AUTOSAR XML (schema 00048)
package /ComponentTypes
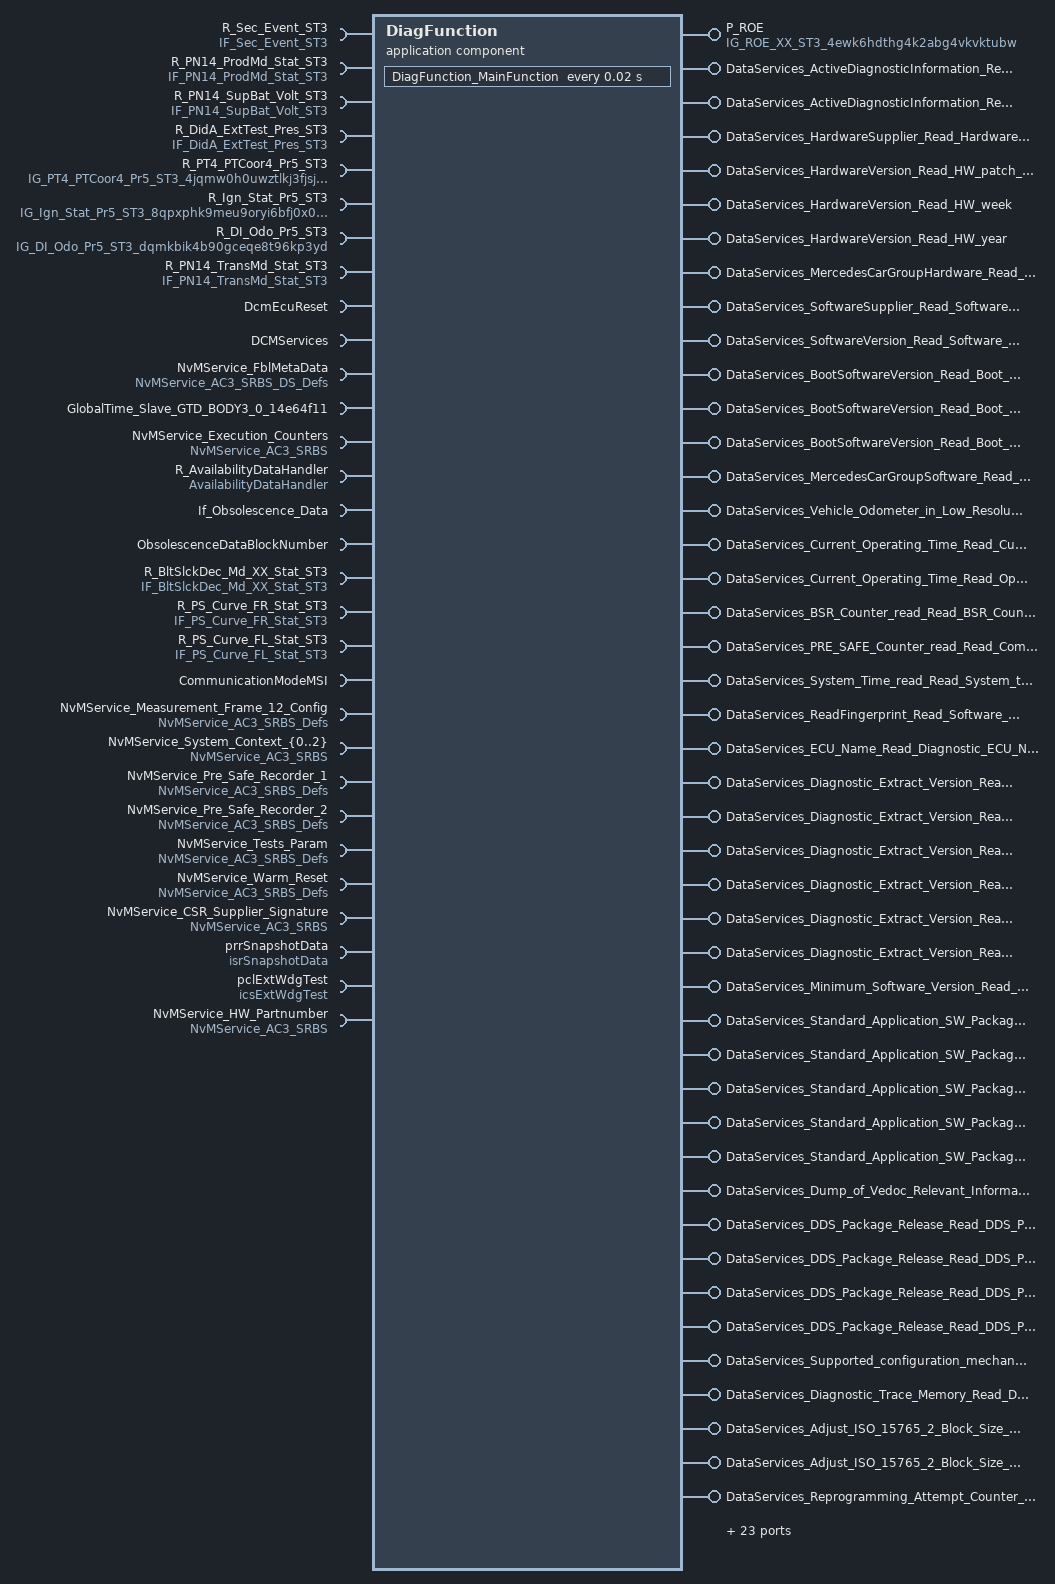
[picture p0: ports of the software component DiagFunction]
  application sw component type DiagFunction
    provide port P_ROE: nonqueued-sender-com-spec{data-element=ROE_XX_ST3, init-value=constant-reference=XDIS_epntk9hnintc34egvtksqi4oo}, provided-interface=IG_ROE_XX_ST3_4ewk6hdthg4k2abg4vkvktubw  # Response on Event (degraded)
    9 x require port:
      R_Sec_Event_ST3: nonqueued-receiver-com-spec{data-element=Data, init-value=constant-reference=XDIS_6146w3b2vgdunnu49c413rpbf}, required-interface=IF_Sec_Event_ST3  # Security event
      R_PN14_ProdMd_Stat_ST3: nonqueued-receiver-com-spec{data-element=PN14_ProdMd_Stat_ST3, init-value=constant-reference=XDIS_1sbl03n5g1wzhawz3y1aoi9p4}, required-interface=IF_PN14_ProdMd_Stat_ST3  # Powernet production mode state
      R_PN14_SupBat_Volt_ST3: nonqueued-receiver-com-spec{data-element=PN14_SupBat_Volt_ST3, init-value=constant-reference=XDIS_1d3ai2d8h1n3nb7ayhambew4d}, required-interface=IF_PN14_SupBat_Volt_ST3  # Supply battery voltage
      R_DidA_ExtTest_Pres_ST3: nonqueued-receiver-com-spec{data-element=DidA_ExtTest_Pres_ST3, init-value=constant-reference=XDIS_ays1a6ktv25pr5ggjl5ntdf5h}, required-interface=IF_DidA_ExtTest_Pres_ST3  # DidA external tester present
      R_PT4_PTCoor4_Pr5_ST3: nonqueued-receiver-com-spec{data-element=PT4_PTCoor4_Pr5_ST3, end-to-end-transformation-com-spec-props=disable-end-to-end-check=true, init-value=constant-reference=XDIS_9yh6bo4rxot1fkk0920219751}, required-interface=IG_PT4_PTCoor4_Pr5_ST3_4jqmw0h0uwztlkj3fjsj9fpfe  # PT4_PTCoor4_Pr5_ST3 (degraded)
      R_Ign_Stat_Pr5_ST3: nonqueued-receiver-com-spec{data-element=Ign_Stat_Pr5_ST3, end-to-end-transformation-com-spec-props=disable-end-to-end-check=false, enable-update=true, filter=data-filter-type=ALWAYS, init-value=constant-reference=XDIS_cfagkw6zyn9r952v5onwpwdur}, required-interface=IG_Ign_Stat_Pr5_ST3_8qpxphk9meu9oryi6bfj0x04b  # Ignition state (degraded)
      R_DI_Odo_Pr5_ST3: nonqueued-receiver-com-spec{data-element=DI_Odo_Pr5_ST3, end-to-end-transformation-com-spec-props=disable-end-to-end-check=true, init-value=constant-reference=XDIS_6b75pabydagdo3iwsn1mn0uh1}, required-interface=IG_DI_Odo_Pr5_ST3_dqmkbik4b90gceqe8t96kp3yd  # DriverInformation Odometer (degraded)
      R_PN14_TransMd_Stat_ST3: nonqueued-receiver-com-spec{data-element=PN14_TransMd_Stat_ST3, filter=data-filter-type=ALWAYS, init-value=constant-reference=XDIS_csegq0grcmpyfro5u6kyzxmql}, required-interface=IF_PN14_TransMd_Stat_ST3  # Powernet transport mode status
      DcmEcuReset: mode-switch-receiver-com-spec=DcmEcuReset, required-interface=DcmEcuReset
    43 x provide port:
      DataServices_ActiveDiagnosticInformation_Read_Identification: provided-com-specs=[{operation=ConditionCheckRead, queue-length=1}, {operation=ReadData, queue-length=1}], provided-interface=DataServices_ActiveDiagnosticInformation_Read_Identification
      DataServices_ActiveDiagnosticInformation_Read_Session: provided-com-specs=[{operation=ConditionCheckRead, queue-length=1}, {operation=ReadData, queue-length=1}], provided-interface=DataServices_ActiveDiagnosticInformation_Read_Session
      DataServices_HardwareSupplier_Read_Hardware_Supplier_Identification: provided-com-specs=[{operation=ConditionCheckRead, queue-length=1}, {operation=ReadData, queue-length=1}], provided-interface=DataServices_HardwareSupplier_Read_Hardware_Supplier_Identification
      DataServices_HardwareVersion_Read_HW_patch_level: provided-com-specs=[{operation=ConditionCheckRead, queue-length=1}, {operation=ReadData, queue-length=1}], provided-interface=DataServices_HardwareVersion_Read_HW_patch_level
      DataServices_HardwareVersion_Read_HW_week: provided-com-specs=[{operation=ConditionCheckRead, queue-length=1}, {operation=ReadData, queue-length=1}], provided-interface=DataServices_HardwareVersion_Read_HW_week
      DataServices_HardwareVersion_Read_HW_year: provided-com-specs=[{operation=ConditionCheckRead, queue-length=1}, {operation=ReadData, queue-length=1}], provided-interface=DataServices_HardwareVersion_Read_HW_year
      DataServices_MercedesCarGroupHardware_Read_Hardware_Part_Number: provided-com-specs=[{operation=ConditionCheckRead, queue-length=1}, {operation=ReadData, queue-length=1}], provided-interface=DataServices_MercedesCarGroupHardware_Read_Hardware_Part_Number
      DataServices_SoftwareSupplier_Read_Software_Logical_Block_Supplier_Identification: provided-interface=DataServices_SoftwareSupplier_Read_Software_Logical_Block_Supplier_Identification
        provided-com-specs:
          operation=ConditionCheckRead, queue-length=1
          operation=ReadDataLength, queue-length=1
          operation=ReadData, queue-length=1
      DataServices_SoftwareVersion_Read_Software_Logical_Block_Version_Information: provided-interface=DataServices_SoftwareVersion_Read_Software_Logical_Block_Version_Information
        provided-com-specs:
          operation=ConditionCheckRead, queue-length=1
          operation=ReadDataLength, queue-length=1
          operation=ReadData, queue-length=1
      DataServices_BootSoftwareVersion_Read_Boot_SW_year: provided-com-specs=[{operation=ConditionCheckRead, queue-length=1}, {operation=ReadData, queue-length=1}], provided-interface=DataServices_BootSoftwareVersion_Read_Boot_SW_year
      DataServices_BootSoftwareVersion_Read_Boot_SW_week: provided-com-specs=[{operation=ConditionCheckRead, queue-length=1}, {operation=ReadData, queue-length=1}], provided-interface=DataServices_BootSoftwareVersion_Read_Boot_SW_week
      DataServices_BootSoftwareVersion_Read_Boot_SW_patch_level: provided-com-specs=[{operation=ConditionCheckRead, queue-length=1}, {operation=ReadData, queue-length=1}], provided-interface=DataServices_BootSoftwareVersion_Read_Boot_SW_patch_level
      DataServices_MercedesCarGroupSoftware_Read_Software_Logical_Block_Numbers: provided-interface=DataServices_MercedesCarGroupSoftware_Read_Software_Logical_Block_Numbers
        provided-com-specs:
          operation=ConditionCheckRead, queue-length=1
          operation=ReadDataLength, queue-length=1
          operation=ReadData, queue-length=1
      DataServices_Vehicle_Odometer_in_Low_Resolution_Read_Vehicle_Odometer_in_Low_Resolution: provided-com-specs=[{operation=ConditionCheckRead, queue-length=1}, {operation=ReadData, queue-length=1}], provided-interface=DataServices_Vehicle_Odometer_in_Low_Resolution_Read_Vehicle_Odometer_in_Low_Resolution
      DataServices_Current_Operating_Time_Read_Current_Operating_Time: provided-com-specs=[{operation=ConditionCheckRead, queue-length=1}, {operation=ReadData, queue-length=1}], provided-interface=DataServices_Current_Operating_Time_Read_Current_Operating_Time
      DataServices_Current_Operating_Time_Read_Operating_Time_Status: provided-com-specs=[{operation=ConditionCheckRead, queue-length=1}, {operation=ReadData, queue-length=1}], provided-interface=DataServices_Current_Operating_Time_Read_Operating_Time_Status
      DataServices_BSR_Counter_read_Read_BSR_Counter: provided-com-specs=[{operation=ConditionCheckRead, queue-length=1}, {operation=ReadData, queue-length=1}], provided-interface=DataServices_BSR_Counter_read_Read_BSR_Counter
      DataServices_PRE_SAFE_Counter_read_Read_CombinedDataElement: provided-interface=DataServices_PRE_SAFE_Counter_read_Read_CombinedDataElement
        provided-com-specs:
          operation=WriteData, queue-length=1
          operation=ConditionCheckRead, queue-length=1
          operation=ReadDataLength, queue-length=1
          operation=ReadData, queue-length=1
      DataServices_System_Time_read_Read_System_time: provided-com-specs=[{operation=ConditionCheckRead, queue-length=1}, {operation=ReadData, queue-length=1}], provided-interface=DataServices_System_Time_read_Read_System_time
      DataServices_ReadFingerprint_Read_Software_Fingerprint_s: provided-interface=DataServices_ReadFingerprint_Read_Software_Fingerprint_s
        provided-com-specs:
          operation=ConditionCheckRead, queue-length=1
          operation=ReadDataLength, queue-length=1
          operation=ReadData, queue-length=1
      DataServices_ECU_Name_Read_Diagnostic_ECU_Name: provided-interface=DataServices_ECU_Name_Read_Diagnostic_ECU_Name
        provided-com-specs:
          operation=ConditionCheckRead, queue-length=1
          operation=ReadDataLength, queue-length=1
          operation=ReadData, queue-length=1
      DataServices_Diagnostic_Extract_Version_Read_Exported_Diagnostic_Variant: provided-com-specs=[{operation=ConditionCheckRead, queue-length=1}, {operation=ReadData, queue-length=1}], provided-interface=DataServices_Diagnostic_Extract_Version_Read_Exported_Diagnostic_Variant
      DataServices_Diagnostic_Extract_Version_Read_Diagnostic_Extract_Patch_Version: provided-com-specs=[{operation=ConditionCheckRead, queue-length=1}, {operation=ReadData, queue-length=1}], provided-interface=DataServices_Diagnostic_Extract_Version_Read_Diagnostic_Extract_Patch_Version
      DataServices_Diagnostic_Extract_Version_Read_Diagnostic_Extract_Minor_Version: provided-com-specs=[{operation=ConditionCheckRead, queue-length=1}, {operation=ReadData, queue-length=1}], provided-interface=DataServices_Diagnostic_Extract_Version_Read_Diagnostic_Extract_Minor_Version
      DataServices_Diagnostic_Extract_Version_Read_Diagnostic_Extract_Major_Version: provided-com-specs=[{operation=ConditionCheckRead, queue-length=1}, {operation=ReadData, queue-length=1}], provided-interface=DataServices_Diagnostic_Extract_Version_Read_Diagnostic_Extract_Major_Version
      DataServices_Diagnostic_Extract_Version_Read_DDM_Version: provided-com-specs=[{operation=ConditionCheckRead, queue-length=1}, {operation=ReadData, queue-length=1}], provided-interface=DataServices_Diagnostic_Extract_Version_Read_DDM_Version
      DataServices_Diagnostic_Extract_Version_Read_CANdela_Version: provided-com-specs=[{operation=ConditionCheckRead, queue-length=1}, {operation=ReadData, queue-length=1}], provided-interface=DataServices_Diagnostic_Extract_Version_Read_CANdela_Version
      DataServices_Minimum_Software_Version_Read_Minimum_Software_Version: provided-interface=DataServices_Minimum_Software_Version_Read_Minimum_Software_Version
        provided-com-specs:
          operation=ConditionCheckRead, queue-length=1
          operation=ReadDataLength, queue-length=1
          operation=ReadData, queue-length=1
      DataServices_Standard_Application_SW_Package_Information_Read_Supplier_Identification: provided-com-specs=[{operation=ConditionCheckRead, queue-length=1}, {operation=ReadData, queue-length=1}], provided-interface=DataServices_Standard_Application_SW_Package_Information_Read_Supplier_Identification
      DataServices_Standard_Application_SW_Package_Information_Read_Standard_Application_SW_Package_Patch_Level: provided-com-specs=[{operation=ConditionCheckRead, queue-length=1}, {operation=ReadData, queue-length=1}], provided-interface=DataServices_Standard_Application_SW_Package_Information_Read_Standard_Application_SW_Package_Patch_Level
      DataServices_Standard_Application_SW_Package_Information_Read_Standard_Application_SW_Package_Minor_Version: provided-com-specs=[{operation=ConditionCheckRead, queue-length=1}, {operation=ReadData, queue-length=1}], provided-interface=DataServices_Standard_Application_SW_Package_Information_Read_Standard_Application_SW_Package_Minor_Version
      DataServices_Standard_Application_SW_Package_Information_Read_Standard_Application_SW_Package_Major_Version: provided-com-specs=[{operation=ConditionCheckRead, queue-length=1}, {operation=ReadData, queue-length=1}], provided-interface=DataServices_Standard_Application_SW_Package_Information_Read_Standard_Application_SW_Package_Major_Version
      DataServices_Standard_Application_SW_Package_Information_Read_Standard_Application_SW_Package_Build_Version: provided-com-specs=[{operation=ConditionCheckRead, queue-length=1}, {operation=ReadData, queue-length=1}], provided-interface=DataServices_Standard_Application_SW_Package_Information_Read_Standard_Application_SW_Package_Build_Version
      DataServices_Dump_of_Vedoc_Relevant_Information_Read_PatchedObject: provided-interface=DataServices_Dump_of_Vedoc_Relevant_Information_Read_PatchedObject
        provided-com-specs:
          operation=ConditionCheckRead, queue-length=1
          operation=ReadDataLength, queue-length=1
          operation=ReadData, queue-length=1
      DataServices_DDS_Package_Release_Read_DDS_Package_Release_of_Boot_Software_Year_Boot: provided-com-specs=[{operation=ConditionCheckRead, queue-length=1}, {operation=ReadData, queue-length=1}], provided-interface=DataServices_DDS_Package_Release_Read_DDS_Package_Release_of_Boot_Software_Year_Boot
      DataServices_DDS_Package_Release_Read_DDS_Package_Release_of_Boot_Software_Month_Boot: provided-com-specs=[{operation=ConditionCheckRead, queue-length=1}, {operation=ReadData, queue-length=1}], provided-interface=DataServices_DDS_Package_Release_Read_DDS_Package_Release_of_Boot_Software_Month_Boot
      DataServices_DDS_Package_Release_Read_DDS_Package_Release_of_Application_Software_Year_Appl: provided-com-specs=[{operation=ConditionCheckRead, queue-length=1}, {operation=ReadData, queue-length=1}], provided-interface=DataServices_DDS_Package_Release_Read_DDS_Package_Release_of_Application_Software_Year_Appl
      DataServices_DDS_Package_Release_Read_DDS_Package_Release_of_Application_Software_Month_Appl: provided-com-specs=[{operation=ConditionCheckRead, queue-length=1}, {operation=ReadData, queue-length=1}], provided-interface=DataServices_DDS_Package_Release_Read_DDS_Package_Release_of_Application_Software_Month_Appl
      DataServices_Supported_configuration_mechanisms_Read_Config_mechanisms: provided-com-specs=[{operation=ConditionCheckRead, queue-length=1}, {operation=ReadData, queue-length=1}], provided-interface=DataServices_Supported_configuration_mechanisms_Read_Config_mechanisms
      DataServices_Diagnostic_Trace_Memory_Read_Diagnostic_Trace_Memory: provided-interface=DataServices_Diagnostic_Trace_Memory_Read_Diagnostic_Trace_Memory
        provided-com-specs:
          operation=WriteData, queue-length=1
          operation=ConditionCheckRead, queue-length=1
          operation=ReadData, queue-length=1
      DataServices_Adjust_ISO_15765_2_Block_Size_and_STmin_Parameter_Read_STmin_Value_as_defined_in_ISO_15765_2: provided-interface=DataServices_Adjust_ISO_15765_2_Block_Size_and_STmin_Parameter_Read_STmin_Value_as_defined_in_ISO_15765_2
        provided-com-specs:
          operation=WriteData, queue-length=1
          operation=ConditionCheckRead, queue-length=1
          operation=ReadData, queue-length=1
      DataServices_Adjust_ISO_15765_2_Block_Size_and_STmin_Parameter_Read_Block_Size_Value_as_defined_in_ISO_15765_2: provided-interface=DataServices_Adjust_ISO_15765_2_Block_Size_and_STmin_Parameter_Read_Block_Size_Value_as_defined_in_ISO_15765_2
        provided-com-specs:
          operation=WriteData, queue-length=1
          operation=ConditionCheckRead, queue-length=1
          operation=ReadData, queue-length=1
      DataServices_Reprogramming_Attempt_Counter_Read_Reprogramming_Attempts: provided-interface=DataServices_Reprogramming_Attempt_Counter_Read_Reprogramming_Attempts
        provided-com-specs:
          operation=ConditionCheckRead, queue-length=1
          operation=ReadDataLength, queue-length=1
          operation=ReadData, queue-length=1
    require port DCMServices: required-com-specs=[GetRequestKind, SetActiveDiagnostic, ResetToDefaultSession, GetSesCtrlType, GetActiveProtocol], required-interface=DCMServices
    provide port RoutineServices_Routine_PreCheckProgrammingDependencies_Start: server-com-spec{operation=Start, queue-length=1}, provided-interface=RoutineServices_Routine_PreCheckProgrammingDependencies_Start
    provide port RoutineServices_Routine_Synchronize_to_Non_volatile_Memory_Start: provided-interface=RoutineServices_Routine_Synchronize_to_Non_volatile_Memory_Start
      provided-com-specs:
        operation=RequestResults, queue-length=1
        operation=Stop, queue-length=1
        operation=Start, queue-length=1
    require port NvMService_FblMetaData: required-interface=NvMService_AC3_SRBS_DS_Defs
      required-com-specs:
        EraseBlock
        InvalidateNvBlock
        GetDataIndex
        SetDataIndex
        RestoreBlockDefaults
        WriteBlock
        ReadBlock
        SetRamBlockStatus
        GetErrorStatus
    provide port StbM_MeasurementNotification_GTD_BODY3_0_14e64f11: server-com-spec{operation=SyncTimeRecordBlock, queue-length=1}, provided-interface=StbM_MeasurementNotification_GTD_BODY3_0_14e64f11
    require port GlobalTime_Slave_GTD_BODY3_0_14e64f11: required-com-specs=[GetSyncTimeRecordHead, GetTimeBaseStatus, GetTimeLeap, GetRateDeviation, GetCurrentTime], required-interface=GlobalTime_Slave_GTD_BODY3_0_14e64f11
    provide port DataServices_Standard_Application_SW_Package_Information_Read_AUTOSAR_Platform: provided-com-specs=[{operation=ConditionCheckRead, queue-length=1}, {operation=ReadData, queue-length=1}], provided-interface=DataServices_Standard_Application_SW_Package_Information_Read_AUTOSAR_Platform
    require port NvMService_Execution_Counters: required-com-specs=[EraseBlock, InvalidateNvBlock, WriteBlock, ReadBlock, SetRamBlockStatus, GetErrorStatus], required-interface=NvMService_AC3_SRBS
    provide port CallbackDTCStatusChange: server-com-spec{operation=DTCStatusChanged, queue-length=1}, provided-interface=CallbackDTCStatusChange
    provide port DataServices_Global_Time_Sync_Measured_Values_Read_GTSM: provided-interface=DataServices_Global_Time_Sync_Measured_Values_Read_GTSM
      provided-com-specs:
        operation=ConditionCheckRead, queue-length=1
        operation=ReadDataLength, queue-length=1
        operation=ReadData, queue-length=1
    require port R_AvailabilityDataHandler: nonqueued-receiver-com-spec{data-element=AvailabilityDataCategory, filter=data-filter-type=ALWAYS, init-value=0}, required-interface=AvailabilityDataHandler
    require port If_Obsolescence_Data: required-com-specs=[Write_Data, Get_Data], required-interface=If_Obsolescence_Data
    require port ObsolescenceDataBlockNumber: nonqueued-receiver-com-spec{data-element=BlockNumber, filter=data-filter-type=ALWAYS}, required-interface=ObsolescenceDataBlockNumber
    16 x provide port:
      Snapshot_DataServices_Data_DID_0x133_Current_Operating_Time: server-com-spec{operation=ReadData, queue-length=1}, provided-interface=CSDataServices_Data_DID_0x133_Current_Operating_Time
      Snapshot_DataServices_Data_DID_0x10a_Vehicle_Odometer_in_Low_Resolution: server-com-spec{operation=ReadData, queue-length=1}, provided-interface=CSDataServices_Data_DID_0x10a_Vehicle_Odometer_in_Low_Resolution
      pseSystemTime: provided-interface=icsSystemTime
        provided-com-specs:
          operation=WriteRelativeSystemTime, queue-length=1
          operation=WriteAbsoluteSystemTime, queue-length=1
          operation=ReadRelativeSystemTime, queue-length=1
          operation=ReadAbsoluteSystemTime, queue-length=1
      DataServices_HSM_Identification_Read_HSM_MB_Version_HW_year: provided-interface=DataServices_HSM_Identification_Read_HSM_MB_Version_HW_year
        provided-com-specs:
          operation=WriteData, queue-length=1
          operation=ConditionCheckRead, queue-length=1
          operation=ReadData, queue-length=1
      DataServices_HSM_Identification_Read_HSM_MB_Partnumber: provided-interface=DataServices_HSM_Identification_Read_HSM_MB_Partnumber
        provided-com-specs:
          operation=WriteData, queue-length=1
          operation=ConditionCheckRead, queue-length=1
          operation=ReadData, queue-length=1
      DataServices_HSM_Identification_Read_HSM_MB_Supplier_Version_HW_patch_level: provided-interface=DataServices_HSM_Identification_Read_HSM_MB_Supplier_Version_HW_patch_level
        provided-com-specs:
          operation=WriteData, queue-length=1
          operation=ConditionCheckRead, queue-length=1
          operation=ReadData, queue-length=1
      DataServices_HSM_Identification_Read_HSM_MB_Supplier_Version_HW_week: provided-interface=DataServices_HSM_Identification_Read_HSM_MB_Supplier_Version_HW_week
        provided-com-specs:
          operation=WriteData, queue-length=1
          operation=ConditionCheckRead, queue-length=1
          operation=ReadData, queue-length=1
      DataServices_HSM_Identification_Read_HSM_MB_Supplier_Version_HW_year: provided-interface=DataServices_HSM_Identification_Read_HSM_MB_Supplier_Version_HW_year
        provided-com-specs:
          operation=WriteData, queue-length=1
          operation=ConditionCheckRead, queue-length=1
          operation=ReadData, queue-length=1
      DataServices_HSM_Identification_Read_HSM_MB_Version_HW_patch_level: provided-interface=DataServices_HSM_Identification_Read_HSM_MB_Version_HW_patch_level
        provided-com-specs:
          operation=WriteData, queue-length=1
          operation=ConditionCheckRead, queue-length=1
          operation=ReadData, queue-length=1
      DataServices_HSM_Identification_Read_HSM_MB_Version_HW_week: provided-interface=DataServices_HSM_Identification_Read_HSM_MB_Version_HW_week
        provided-com-specs:
          operation=WriteData, queue-length=1
          operation=ConditionCheckRead, queue-length=1
          operation=ReadData, queue-length=1
      DataServices_Standard_Application_SW_Package_Information_Read_C_P_Identification: provided-com-specs=[{operation=ConditionCheckRead, queue-length=1}, {operation=ReadData, queue-length=1}], provided-interface=DataServices_Standard_Application_SW_Package_Information_Read_C_P_Identification
      DataServices_Customer_Settings_Read_BltSlckDec_Md_Stat: provided-com-specs=[{operation=ConditionCheckRead, queue-length=1}, {operation=ReadData, queue-length=1}], provided-interface=DataServices_Customer_Settings_Read_BltSlckDec_Md_Stat
      DataServices_Customer_Settings_Read_PS_Curve_Stat: provided-com-specs=[{operation=ConditionCheckRead, queue-length=1}, {operation=ReadData, queue-length=1}], provided-interface=DataServices_Customer_Settings_Read_PS_Curve_Stat
      DataServices_Trust_Model_CSR_Supplier_Signature_Read_Trust_Model_CSR_Supplier_Signature: provided-interface=DataServices_Trust_Model_CSR_Supplier_Signature_Read_Trust_Model_CSR_Supplier_Signature
        provided-com-specs:
          operation=WriteData, queue-length=1
          operation=ConditionCheckRead, queue-length=1
          operation=ReadDataLength, queue-length=1
          operation=ReadData, queue-length=1
      RoutineServices_Routine_Erase_All_Start: server-com-spec{operation=Start, queue-length=1}, provided-interface=RoutineServices_Routine_Erase_All_Start
      RoutineServices_Routine_Force_External_WDG_Start: server-com-spec{operation=Start, queue-length=1}, provided-interface=RoutineServices_Routine_Force_External_WDG_Start
    require port R_BltSlckDec_Md_XX_Stat_ST3: nonqueued-receiver-com-spec{data-element=BltSlckDec_Md_XX_Stat_ST3, filter=data-filter-type=ALWAYS, init-value=constant-reference=XDIS_e0p8eo65xegbkeoit2yb8bj0v}, required-interface=IF_BltSlckDec_Md_XX_Stat_ST3
    require port R_PS_Curve_FR_Stat_ST3: nonqueued-receiver-com-spec{data-element=PS_Curve_FR_Stat_ST3, filter=data-filter-type=ALWAYS}, required-interface=IF_PS_Curve_FR_Stat_ST3
    require port R_PS_Curve_FL_Stat_ST3: nonqueued-receiver-com-spec{data-element=PS_Curve_FL_Stat_ST3, filter=data-filter-type=ALWAYS}, required-interface=IF_PS_Curve_FL_Stat_ST3
    provide port Snapshot_DataServices_Data_DID_0xfd05_Root_Causes: server-com-spec{operation=ReadData, queue-length=1}, provided-interface=CSDataServices_Data_DID_0xfd05_Root_Causes
    13 x require port:
      CommunicationModeMSI: mode-switch-receiver-com-spec{enhanced-mode-api=true, mode-group=Mode}, required-interface=CommunicationModeMSI
      NvMService_Measurement_Frame_12_Config: required-com-specs=[EraseBlock, InvalidateNvBlock, RestoreBlockDefaults, WriteBlock, ReadBlock, SetRamBlockStatus, GetErrorStatus], required-interface=NvMService_AC3_SRBS_Defs
      NvMService_System_Context_{0..2}: required-com-specs=[EraseBlock, InvalidateNvBlock, WriteBlock, ReadBlock, SetRamBlockStatus, GetErrorStatus], required-interface=NvMService_AC3_SRBS
      NvMService_Pre_Safe_Recorder_1: required-com-specs=[EraseBlock, InvalidateNvBlock, RestoreBlockDefaults, WriteBlock, ReadBlock, SetRamBlockStatus, GetErrorStatus], required-interface=NvMService_AC3_SRBS_Defs
      NvMService_Pre_Safe_Recorder_2: required-com-specs=[EraseBlock, InvalidateNvBlock, RestoreBlockDefaults, WriteBlock, ReadBlock, SetRamBlockStatus, GetErrorStatus], required-interface=NvMService_AC3_SRBS_Defs
      NvMService_Tests_Param: required-com-specs=[EraseBlock, InvalidateNvBlock, RestoreBlockDefaults, WriteBlock, ReadBlock, SetRamBlockStatus, GetErrorStatus], required-interface=NvMService_AC3_SRBS_Defs
      NvMService_Warm_Reset: required-com-specs=[EraseBlock, InvalidateNvBlock, RestoreBlockDefaults, WriteBlock, ReadBlock, SetRamBlockStatus, GetErrorStatus], required-interface=NvMService_AC3_SRBS_Defs
      NvMService_CSR_Supplier_Signature: required-com-specs=[EraseBlock, InvalidateNvBlock, WriteBlock, ReadBlock, SetRamBlockStatus, GetErrorStatus], required-interface=NvMService_AC3_SRBS
      prrSnapshotData: nonqueued-receiver-com-spec{data-element=u8SnapshotAecId, filter=data-filter-type=ALWAYS, init-value=255}, required-interface=isrSnapshotData
      pclExtWdgTest: required-com-specs=[LaunchWdgTest, GetWdgTestResult], required-interface=icsExtWdgTest
      NvMService_HW_Partnumber: required-com-specs=[EraseBlock, InvalidateNvBlock, WriteBlock, ReadBlock, SetRamBlockStatus, GetErrorStatus], required-interface=NvMService_AC3_SRBS
    behavior DiagFunction_InternalBehavior: data-type-mapping=[DataTypeMappings_DEV, DataTypeMappingSet_PP4G]
      exclusive area DiagFunction_ExclusiveArea
      ar-typed-per-instance-memorys:
        4 x data, all with sw-calibration-access=READ-ONLY:
          DiagnosticTraceMemory: type=Dcm_Data12ByteType
          CustomerSettings: type=Dcm_Data4092ByteType
          ISO_15675_2_BlockSize: type=Dcm_Data1ByteType
          ISO_15675_2_STmin: type=Dcm_Data1ByteType
      98 x operation invoked event:
        OIT_DataServices_ActiveDiagnosticInformation_Read_Identification_DataServices_ActiveDiagnosticInformation_Read_Identific7067A581: start-on-event=DataServices_ActiveDiagnosticInformation_Read_Identification_ReadData, operation=DataServices_ActiveDiagnosticInformation_Read_Identification.ReadData
        OIT_DataServices_HardwareSupplier_Read_Hardware_Supplier_Identification_DataServices_HardwareSupplier_Read_Hardware_Supp97365F1B: start-on-event=DataServices_HardwareSupplier_Read_Hardware_Supplier_Identification_ConditionCheckRead, operation=DataServices_HardwareSupplier_Read_Hardware_Supplier_Identification.ConditionCheckRead
        OIT_DataServices_HardwareVersion_Read_DataServices_HardwareVersion_Read_HW_year_ConditionCheckRead: start-on-event=DataServices_HardwareVersion_Read_HW_year_ConditionCheckRead, operation=DataServices_HardwareVersion_Read_HW_year.ConditionCheckRead
        OIT_DataServices_MercedesCarGroupHardware_Read_Hardware_Part_Number_DataServices_MercedesCarGroupHardware_Read_Hardware_55196EFA: start-on-event=DataServices_MercedesCarGroupHardware_Read_Hardware_Part_Number_ConditionCheckRead, operation=DataServices_MercedesCarGroupHardware_Read_Hardware_Part_Number.ConditionCheckRead
        OIT_DataServices_ActiveDiagnosticInformation_Read_Session_DataServices_ActiveDiagnosticInformation_Read_Session_ReadData: start-on-event=DataServices_ActiveDiagnosticInformation_Read_Session_ReadData, operation=DataServices_ActiveDiagnosticInformation_Read_Session.ReadData
        OIT_DataServices_SoftwareSupplier_Read_Software_Logical_Block_Supplier_Identification_DataServices_SoftwareSupplier_Read4BC1C9C3: start-on-event=DataServices_SoftwareSupplier_Read_Software_Logical_Block_Supplier_Identification_ReadData, operation=DataServices_SoftwareSupplier_Read_Software_Logical_Block_Supplier_Identification.ReadData
        OIT_DataServices_SoftwareVersion_Read_Software_Logical_Block_Version_Information_DataServices_SoftwareVersion_Read_SoftwF2AC6E69: start-on-event=DataServices_SoftwareVersion_Read_Software_Logical_Block_Version_Information_ReadData, operation=DataServices_SoftwareVersion_Read_Software_Logical_Block_Version_Information.ReadData
        OIT_DataServices_SoftwareVersion_Read_Software_Logical_Block_Version_Information_ReadDataLength_DataServices_SoftwareVerA68B48B5: start-on-event=DataServices_SoftwareVersion_Read_Software_Logical_Block_Version_Information_ReadDataLength, operation=DataServices_SoftwareVersion_Read_Software_Logical_Block_Version_Information.ReadDataLength
        OIT_DataServices_SoftwareVersion_Read_Software_Logical_Block_Version_Information_ReadDataC_DataServices_SoftwareVersion_DE305E56: start-on-event=DataServices_SoftwareVersion_Read_Software_Logical_Block_Version_Information_ConditionCheckRead, operation=DataServices_SoftwareVersion_Read_Software_Logical_Block_Version_Information.ConditionCheckRead
        OIT_DataServices_SoftwareSupplier_Read_Software_Logical_Block_Supplier_Identification_ReadDataLength_DataServices_SoftwaE5662F6A: start-on-event=DataServices_SoftwareSupplier_Read_Software_Logical_Block_Supplier_Identification_ReadDataLength, operation=DataServices_SoftwareSupplier_Read_Software_Logical_Block_Supplier_Identification.ReadDataLength
        OIT_DataServices_SoftwareSupplier_Read_Software_Logical_Block_Supplier_Identification_ConditionCheckRead_DataServices_SoDBA54C26: start-on-event=DataServices_SoftwareSupplier_Read_Software_Logical_Block_Supplier_Identification_ConditionCheckRead, operation=DataServices_SoftwareSupplier_Read_Software_Logical_Block_Supplier_Identification.ConditionCheckRead
        OIT_DataServices_HardwareVersion_Read_DataServices_HardwareVersion_Read_HW_year_ReadData_1: start-on-event=DataServices_HardwareVersion_Read_HW_year_ReadData, operation=DataServices_HardwareVersion_Read_HW_year.ReadData
        OIT_DataServices_MercedesCarGroupHardware_Read_Hardware_Part_Number_DataServices_MercedesCarGroupHardware_Read_Hardware_8E3F07_1: start-on-event=DataServices_MercedesCarGroupHardware_Read_Hardware_Part_Number_ReadData, operation=DataServices_MercedesCarGroupHardware_Read_Hardware_Part_Number.ReadData
        OIT_DataServices_BootSoftwareVersion_ConditionCheckRead_DataServices_BootSoftwareVersion_Read_Boot_SW_year_ConditionCheckRead: start-on-event=DataServices_BootSoftwareVersion_Read_Boot_SW_year_ConditionCheckRead, operation=DataServices_BootSoftwareVersion_Read_Boot_SW_year.ConditionCheckRead
        OIT_DataServices_BootSoftwareVersion_ReadData_DataServices_BootSoftwareVersion_Read_Boot_SW_year_ReadData: start-on-event=DataServices_BootSoftwareVersion_Read_Boot_SW_year_ReadData, operation=DataServices_BootSoftwareVersion_Read_Boot_SW_year.ReadData
        OIT_DataServices_MercedesCarGroupHardware_Read_Software_Part_Number_ConditionCheckRead_DataServices_MercedesCarGroupSoft038C4948: start-on-event=DataServices_MercedesCarGroupHardware_Read_Software_Part_Number_ConditionCheckRead, operation=DataServices_MercedesCarGroupSoftware_Read_Software_Logical_Block_Numbers.ConditionCheckRead
        OIT_DataServices_MercedesCarGroupHardware_Read_Software_Part_Number_ConditionCheckRead_1_DataServices_MercedesCarGroupSo6AE0CD9F: start-on-event=DataServices_MercedesCarGroupHardware_Read_Software_Part_Number_ReadData, operation=DataServices_MercedesCarGroupSoftware_Read_Software_Logical_Block_Numbers.ReadData
        OIT_DataServices_ActiveDiagnosticInformation_Read_Identification_ConditionCheckRead_DataServices_ActiveDiagnosticInforma10A2793D: start-on-event=DataServices_ActiveDiagnosticInformation_Read_Identification_ConditionCheckRead, operation=DataServices_ActiveDiagnosticInformation_Read_Identification.ConditionCheckRead
        OIT_DataServices_ActiveDiagnosticInformation_Read_Session_ConditionCheckRead_DataServices_ActiveDiagnosticInformation_ReD90CDEBC: start-on-event=DataServices_ActiveDiagnosticInformation_Read_Session_ConditionCheckRead, operation=DataServices_ActiveDiagnosticInformation_Read_Session.ConditionCheckRead
        OIT_DataServices_HardwareSupplier_Read_Hardware_Supplier_Identification_1_DataServices_HardwareSupplier_Read_Hardware_Supp: start-on-event=DataServices_HardwareSupplier_Read_Hardware_Supplier_Identification_ReadData, operation=DataServices_HardwareSupplier_Read_Hardware_Supplier_Identification.ReadData
        OIT_DataServices_HardwareVersion_Read_DataServices_HardwareVersion_Read_HW_week_ConditionCheckRead_1: start-on-event=DataServices_HardwareVersion_Read_HW_week_ConditionCheckRead, operation=DataServices_HardwareVersion_Read_HW_week.ConditionCheckRead
        OIT_DataServices_HardwareVersion_Read_DataServices_HardwareVersion_Read_HW_patch_level_ConditionCheckRead_2: start-on-event=DataServices_HardwareVersion_Read_HW_patch_level_ConditionCheckRead, operation=DataServices_HardwareVersion_Read_HW_patch_level.ConditionCheckRead
        OIT_DataServices_HardwareVersion_Read_DataServices_HardwareVersion_Read_HW_week_ReadData_2: start-on-event=DataServices_HardwareVersion_Read_HW_week_ReadData, operation=DataServices_HardwareVersion_Read_HW_week.ReadData
        OIT_DataServices_HardwareVersion_Read_DataServices_HardwareVersion_Read_HW_patch_level_ReadData_3: start-on-event=DataServices_HardwareVersion_Read_HW_patch_level_ReadData, operation=DataServices_HardwareVersion_Read_HW_patch_level.ReadData
        OIT_DataServices_BootSoftwareVersion_ConditionCheckRead_1_DataServices_BootSoftwareVersion_Read_Boot_SW_week_ConditionCheckRead: start-on-event=DataServices_BootSoftwareVersion_Read_Boot_SW_week_ConditionCheckRead, operation=DataServices_BootSoftwareVersion_Read_Boot_SW_week.ConditionCheckRead
        OIT_DataServices_BootSoftwareVersion_ConditionCheckRead_1_1_DataServices_BootSoftwareVersion_Read_Boot_SW_patch_leve: start-on-event=DataServices_BootSoftwareVersion_Read_Boot_SW_patch_level_ConditionCheckRead, operation=DataServices_BootSoftwareVersion_Read_Boot_SW_patch_level.ConditionCheckRead
        OIT_DataServices_BootSoftwareVersion_ReadData_1_DataServices_BootSoftwareVersion_Read_Boot_SW_week_ReadData: start-on-event=DataServices_BootSoftwareVersion_Read_Boot_SW_week_ReadData, operation=DataServices_BootSoftwareVersion_Read_Boot_SW_week.ReadData
        OIT_DataServices_BootSoftwareVersion_ReadData_1_1_DataServices_BootSoftwareVersion_Read_Boot_SW_patch_level_ReadData: start-on-event=DataServices_BootSoftwareVersion_Read_Boot_SW_patch_level_ReadData, operation=DataServices_BootSoftwareVersion_Read_Boot_SW_patch_level.ReadData
        OIT_Runnable_DataServices_Vehicle_Odometer_in_Low_Resolution_Read_Vehicle_Odometer_in_Low_Resolution_ConditionCheckRead: start-on-event=DataServices_Vehicle_Odometer_in_Low_Resolution_Read_Vehicle_Odometer_in_Low_Resolution_ConditionCheckRead, operation=DataServices_Vehicle_Odometer_in_Low_Resolution_Read_Vehicle_Odometer_in_Low_Resolution.ConditionCheckRead
        OIT_DataServices_Vehicle_Odometer_in_Low_Resolution_Read_Vehicle_Odometer_in_Low_Resolution_ReadData_DataServices_Vehicl8457E95B: start-on-event=DataServices_Vehicle_Odometer_in_Low_Resolution_Read_Vehicle_Odometer_in_Low_Resolution_ReadData, operation=DataServices_Vehicle_Odometer_in_Low_Resolution_Read_Vehicle_Odometer_in_Low_Resolution.ReadData
        OIT_Runnable_DataServices_Current_Operating_Time_Read_Current_Operating_Time_ConditionCheckRead: start-on-event=DataServices_Current_Operating_Time_Read_Current_Operating_Time_ConditionCheckRead, operation=DataServices_Current_Operating_Time_Read_Current_Operating_Time.ConditionCheckRead
        OIT_DataServices_Current_Operating_Time_Read_Current_Operating_Time_ReadData_DataServices_Current_Operating_Time_Read_Cu8A69F1C2: start-on-event=DataServices_Current_Operating_Time_Read_Current_Operating_Time_ReadData, operation=DataServices_Current_Operating_Time_Read_Current_Operating_Time.ReadData
        OIT_Runnable_DataServices_Current_Operating_Time_Read_Operating_Time_Status_ConditionCheckRead: start-on-event=DataServices_Current_Operating_Time_Read_Operating_Time_Status_ConditionCheckRead, operation=DataServices_Current_Operating_Time_Read_Operating_Time_Status.ConditionCheckRead
        OIT_DataServices_Current_Operating_Time_Read_Operating_Time_Status_ReadData_DataServices_Current_Operating_Time_Read_Ope8F9C9D2D: start-on-event=DataServices_Current_Operating_Time_Read_Operating_Time_Status_ReadData, operation=DataServices_Current_Operating_Time_Read_Operating_Time_Status.ReadData
        OIT_Runnable_DataServices_BSR_Counter_read_Read_BSR_Counter_ConditionCheckRead: start-on-event=DataServices_BSR_Counter_read_Read_BSR_Counter_ConditionCheckRead, operation=DataServices_BSR_Counter_read_Read_BSR_Counter.ConditionCheckRead
        OIT_DataServices_BSR_Counter_read_Read_BSR_Counter_ReadData_DataServices_BSR_Counter_read_Read_BSR_Counter_ReadData: start-on-event=DataServices_BSR_Counter_read_Read_BSR_Counter_ReadData, operation=DataServices_BSR_Counter_read_Read_BSR_Counter.ReadData
        OIT_Runnable_DataServices_PRE_SAFE_Counter_read_Read_CombinedDataElement_ConditionCheckRead: start-on-event=DataServices_PRE_SAFE_Counter_read_Read_CombinedDataElement_ConditionCheckRead, operation=DataServices_PRE_SAFE_Counter_read_Read_CombinedDataElement.ConditionCheckRead
        OIT_DataServices_PRE_SAFE_Counter_read_Read_CombinedDataElement_ReadData_DataServices_PRE_SAFE_Counter_read_Read_Combine300B2AA5: start-on-event=DataServices_PRE_SAFE_Counter_read_Read_CombinedDataElement_ReadData, operation=DataServices_PRE_SAFE_Counter_read_Read_CombinedDataElement.ReadData
        OIT_DataServices_PRE_SAFE_Counter_read_Read_CombinedDataElement_ReadDataLength_DataServices_PRE_SAFE_Counter_read_Read_C2B70C924: start-on-event=DataServices_PRE_SAFE_Counter_read_Read_CombinedDataElement_ReadDataLength, operation=DataServices_PRE_SAFE_Counter_read_Read_CombinedDataElement.ReadDataLength
        OIT_DataServices_PRE_SAFE_Counter_read_Read_CombinedDataElement_WriteData_DataServices_PRE_SAFE_Counter_read_Read_CombinC649130F: start-on-event=DataServices_PRE_SAFE_Counter_read_Read_CombinedDataElement_WriteData, operation=DataServices_PRE_SAFE_Counter_read_Read_CombinedDataElement.WriteData
        OIT_Runnable_DataServices_System_Time_read_Read_System_time_ConditionCheckRead: start-on-event=DataServices_System_Time_read_Read_System_time_ConditionCheckRead, operation=DataServices_System_Time_read_Read_System_time.ConditionCheckRead
        OIT_DataServices_System_Time_read_Read_System_time_ReadData_DataServices_System_Time_read_Read_System_time_ReadData: start-on-event=DataServices_System_Time_read_Read_System_time_ReadData, operation=DataServices_System_Time_read_Read_System_time.ReadData
        OIT_Runnable_DataServices_ReadFingerprint_Read_Software_Fingerprint_s_ConditionCheckRead: start-on-event=DataServices_ReadFingerprint_Read_Software_Fingerprint_s_ConditionCheckRead, operation=DataServices_ReadFingerprint_Read_Software_Fingerprint_s.ConditionCheckRead
        OIT_DataServices_ReadFingerprint_Read_Software_Fingerprint_s_ReadData_DataServices_ReadFingerprint_Read_Software_Fingerp59D6833C: start-on-event=DataServices_ReadFingerprint_Read_Software_Fingerprint_s_ReadData, operation=DataServices_ReadFingerprint_Read_Software_Fingerprint_s.ReadData
        OIT_DataServices_ReadFingerprint_Read_Software_Fingerprint_s_ReadDataLength_DataServices_ReadFingerprint_Read_Software_F832B362C: start-on-event=DataServices_ReadFingerprint_Read_Software_Fingerprint_s_ReadDataLength, operation=DataServices_ReadFingerprint_Read_Software_Fingerprint_s.ReadDataLength
        OIT_Runnable_DataServices_ECU_Name_Read_Diagnostic_ECU_Name_ConditionCheckRead: start-on-event=DataServices_ECU_Name_Read_Diagnostic_ECU_Name_ConditionCheckRead, operation=DataServices_ECU_Name_Read_Diagnostic_ECU_Name.ConditionCheckRead
        OIT_DataServices_ECU_Name_Read_Diagnostic_ECU_Name_ReadDataLength_DataServices_ECU_Name_Read_Diagnostic_ECU_Name_ReadDataLength: start-on-event=DataServices_ECU_Name_Read_Diagnostic_ECU_Name_ReadDataLength, operation=DataServices_ECU_Name_Read_Diagnostic_ECU_Name.ReadDataLength
        OIT_DataServices_ECU_Name_Read_Diagnostic_ECU_Name_ReadData_DataServices_ECU_Name_Read_Diagnostic_ECU_Name_ReadData: start-on-event=DataServices_ECU_Name_Read_Diagnostic_ECU_Name_ReadData, operation=DataServices_ECU_Name_Read_Diagnostic_ECU_Name.ReadData
        OIT_Runnable_DataServices_Diagnostic_Extract_Version_Read_CANdela_Version_ConditionCheckRead: start-on-event=DataServices_Diagnostic_Extract_Version_Read_CANdela_Version_ConditionCheckRead, operation=DataServices_Diagnostic_Extract_Version_Read_CANdela_Version.ConditionCheckRead
        OIT_DataServices_Diagnostic_Extract_Version_Read_CANdela_Version_ReadData_DataServices_Diagnostic_Extract_Version_Read_CDA458A82: start-on-event=DataServices_Diagnostic_Extract_Version_Read_CANdela_Version_ReadData, operation=DataServices_Diagnostic_Extract_Version_Read_CANdela_Version.ReadData
        OIT_Runnable_DataServices_Diagnostic_Extract_Version_Read_DDM_Version_ConditionCheckRead: start-on-event=DataServices_Diagnostic_Extract_Version_Read_DDM_Version_ConditionCheckRead, operation=DataServices_Diagnostic_Extract_Version_Read_DDM_Version.ConditionCheckRead
        OIT_DataServices_Diagnostic_Extract_Version_Read_DDM_Version_ReadData_DataServices_Diagnostic_Extract_Version_Read_DDM_VC2FF09A9: start-on-event=DataServices_Diagnostic_Extract_Version_Read_DDM_Version_ReadData, operation=DataServices_Diagnostic_Extract_Version_Read_DDM_Version.ReadData
        OIT_Runnable_DataServices_Diagnostic_Extract_Version_Read_Diagnostic_Extract_Major_Version_ConditionCheckRead: start-on-event=DataServices_Diagnostic_Extract_Version_Read_Diagnostic_Extract_Major_Version_ConditionCheckRead, operation=DataServices_Diagnostic_Extract_Version_Read_Diagnostic_Extract_Major_Version.ConditionCheckRead
        OIT_DataServices_Diagnostic_Extract_Version_Read_Diagnostic_Extract_Minor_Version_ReadData_DataServices_Diagnostic_ExtraABF51EB4: start-on-event=DataServices_Diagnostic_Extract_Version_Read_Diagnostic_Extract_Minor_Version_ReadData, operation=DataServices_Diagnostic_Extract_Version_Read_Diagnostic_Extract_Minor_Version.ReadData
        OIT_DataServices_Diagnostic_Extract_Version_Read_Diagnostic_Extract_Patch_Version_ReadData_DataServices_Diagnostic_ExtraC234900D: start-on-event=DataServices_Diagnostic_Extract_Version_Read_Diagnostic_Extract_Patch_Version_ReadData, operation=DataServices_Diagnostic_Extract_Version_Read_Diagnostic_Extract_Patch_Version.ReadData
        OIT_DataServices_Diagnostic_Extract_Version_Read_Diagnostic_Extract_Patch_Version_ConditionCheckRead_DataServices_Diagno364AF496: start-on-event=DataServices_Diagnostic_Extract_Version_Read_Diagnostic_Extract_Patch_Version_ConditionCheckRead, operation=DataServices_Diagnostic_Extract_Version_Read_Diagnostic_Extract_Patch_Version.ConditionCheckRead
        OIT_DataServices_Diagnostic_Extract_Version_Read_Diagnostic_Extract_Major_Version_ReadData_DataServices_Diagnostic_Extra871CC8B7: start-on-event=DataServices_Diagnostic_Extract_Version_Read_Diagnostic_Extract_Major_Version_ReadData, operation=DataServices_Diagnostic_Extract_Version_Read_Diagnostic_Extract_Major_Version.ReadData
        OIT_DataServices_Diagnostic_Extract_Version_Read_Diagnostic_Extract_Minor_Version_ConditionCheckRead_DataServices_Diagno232E6B3C: start-on-event=DataServices_Diagnostic_Extract_Version_Read_Diagnostic_Extract_Minor_Version_ConditionCheckRead, operation=DataServices_Diagnostic_Extract_Version_Read_Diagnostic_Extract_Minor_Version.ConditionCheckRead
        OIT_Runnable_DataServices_Diagnostic_Extract_Version_Read_Exported_Diagnostic_Variant_ConditionCheckRead: start-on-event=DataServices_Diagnostic_Extract_Version_Read_Exported_Diagnostic_Variant_ConditionCheckRead, operation=DataServices_Diagnostic_Extract_Version_Read_Exported_Diagnostic_Variant.ConditionCheckRead
        OIT_DataServices_Diagnostic_Extract_Version_Read_Exported_Diagnostic_Variant_ReadData_DataServices_Diagnostic_Extract_VeD80112BF: start-on-event=DataServices_Diagnostic_Extract_Version_Read_Exported_Diagnostic_Variant_ReadData, operation=DataServices_Diagnostic_Extract_Version_Read_Exported_Diagnostic_Variant.ReadData
        OIT_Runnable_DataServices_Minimum_Software_Version_Read_Minimum_Software_Version_ConditionCheckRead: start-on-event=DataServices_Minimum_Software_Version_Read_Minimum_Software_Version_ConditionCheckRead, operation=DataServices_Minimum_Software_Version_Read_Minimum_Software_Version.ConditionCheckRead
        OIT_DataServices_Minimum_Software_Version_Read_Minimum_Software_Version_ReadData_DataServices_Minimum_Software_Version_R55FFE849: start-on-event=DataServices_Minimum_Software_Version_Read_Minimum_Software_Version_ReadData, operation=DataServices_Minimum_Software_Version_Read_Minimum_Software_Version.ReadData
        OIT_DataServices_Minimum_Software_Version_Read_Minimum_Software_Version_ReadDataLength_DataServices_Minimum_Software_Ver44C272CF: start-on-event=DataServices_Minimum_Software_Version_Read_Minimum_Software_Version_ReadDataLength, operation=DataServices_Minimum_Software_Version_Read_Minimum_Software_Version.ReadDataLength
        OIT_Runnable_DataServices_Standard_Application_SW_Package_Information_Read_Standard_Application_SW_Package_Build_Version46B493C3: start-on-event=DataServices_Standard_Application_SW_Package_Information_Read_Standard_Application_SW_Package_Build_Version_ConditionCheckRead, operation=DataServices_Standard_Application_SW_Package_Information_Read_Standard_Application_SW_Package_Build_Version.ConditionCheckRead
        OIT_DataServices_Standard_Application_SW_Package_Information_Read_Standard_Application_SW_Package_Build_Version_ReadDataBEB026D8: start-on-event=DataServices_Standard_Application_SW_Package_Information_Read_Standard_Application_SW_Package_Build_Version_ReadData, operation=DataServices_Standard_Application_SW_Package_Information_Read_Standard_Application_SW_Package_Build_Version.ReadData
        OIT_Runnable_DataServices_Standard_Application_SW_Package_Information_Read_Standard_Application_SW_Package_Major_Version379E0ABC: start-on-event=DataServices_Standard_Application_SW_Package_Information_Read_Standard_Application_SW_Package_Major_Version_ConditionCheckRead, operation=DataServices_Standard_Application_SW_Package_Information_Read_Standard_Application_SW_Package_Major_Version.ConditionCheckRead
        OIT_DataServices_Standard_Application_SW_Package_Information_Read_Standard_Application_SW_Package_Major_Version_ReadData97FDC4FB: start-on-event=DataServices_Standard_Application_SW_Package_Information_Read_Standard_Application_SW_Package_Major_Version_ReadData, operation=DataServices_Standard_Application_SW_Package_Information_Read_Standard_Application_SW_Package_Major_Version.ReadData
        OIT_Runnable_DataServices_Standard_Application_SW_Package_Information_Read_Standard_Application_SW_Package_Minor_VersionB122C014: start-on-event=DataServices_Standard_Application_SW_Package_Information_Read_Standard_Application_SW_Package_Minor_Version_ConditionCheckRead, operation=DataServices_Standard_Application_SW_Package_Information_Read_Standard_Application_SW_Package_Minor_Version.ConditionCheckRead
        OIT_DataServices_Standard_Application_SW_Package_Information_Read_Standard_Application_SW_Package_Minor_Version_ReadData3C226703: start-on-event=DataServices_Standard_Application_SW_Package_Information_Read_Standard_Application_SW_Package_Minor_Version_ReadData, operation=DataServices_Standard_Application_SW_Package_Information_Read_Standard_Application_SW_Package_Minor_Version.ReadData
        OIT_Runnable_DataServices_Standard_Application_SW_Package_Information_Read_Standard_Application_SW_Package_Patch_Level_C9AB53209: start-on-event=DataServices_Standard_Application_SW_Package_Information_Read_Standard_Application_SW_Package_Patch_Level_ConditionCheckRead, operation=DataServices_Standard_Application_SW_Package_Information_Read_Standard_Application_SW_Package_Patch_Level.ConditionCheckRead
        OIT_DataServices_Standard_Application_SW_Package_Information_Read_Standard_Application_SW_Package_Patch_Level_ReadData_DE8742F2B: start-on-event=DataServices_Standard_Application_SW_Package_Information_Read_Standard_Application_SW_Package_Patch_Level_ReadData, operation=DataServices_Standard_Application_SW_Package_Information_Read_Standard_Application_SW_Package_Patch_Level.ReadData
        OIT_Runnable_DataServices_Standard_Application_SW_Package_Information_Read_Supplier_Identification_ConditionCheckRead: start-on-event=DataServices_Standard_Application_SW_Package_Information_Read_Supplier_Identification_ConditionCheckRead, operation=DataServices_Standard_Application_SW_Package_Information_Read_Supplier_Identification.ConditionCheckRead
        OIT_DataServices_Standard_Application_SW_Package_Information_Read_Supplier_Identification_ReadData_DataServices_Standard5D3874FA: start-on-event=DataServices_Standard_Application_SW_Package_Information_Read_Supplier_Identification_ReadData, operation=DataServices_Standard_Application_SW_Package_Information_Read_Supplier_Identification.ReadData
        OIT_Runnable_DataServices_Dump_of_Vedoc_Relevant_Information_Read_PatchedObject_ConditionCheckRead: start-on-event=DataServices_Dump_of_Vedoc_Relevant_Information_Read_PatchedObject_ConditionCheckRead, operation=DataServices_Dump_of_Vedoc_Relevant_Information_Read_PatchedObject.ConditionCheckRead
        OIT_DataServices_Dump_of_Vedoc_Relevant_Information_Read_PatchedObject_ReadData_DataServices_Dump_of_Vedoc_Relevant_InfoDD2B0555: start-on-event=DataServices_Dump_of_Vedoc_Relevant_Information_Read_PatchedObject_ReadData, operation=DataServices_Dump_of_Vedoc_Relevant_Information_Read_PatchedObject.ReadData
        OIT_Runnable_DataServices_Dump_of_Vedoc_Relevant_Information_Read_PatchedObject_ReadDataLength: start-on-event=DataServices_Dump_of_Vedoc_Relevant_Information_Read_PatchedObject_ReadDataLength, operation=DataServices_Dump_of_Vedoc_Relevant_Information_Read_PatchedObject.ReadDataLength
        OIT_Runnable_DataServices_DDS_Package_Release_Read_DDS_Package_Release_of_Application_Software_Month_Appl_ConditionCheckRead: start-on-event=DataServices_DDS_Package_Release_Read_DDS_Package_Release_of_Application_Software_Month_Appl_ConditionCheckRead, operation=DataServices_DDS_Package_Release_Read_DDS_Package_Release_of_Application_Software_Month_Appl.ConditionCheckRead
        OIT_Runnable_DataServices_DDS_Package_Release_Read_DDS_Package_Release_of_Application_Software_Month_Appl_ReadData: start-on-event=DataServices_DDS_Package_Release_Read_DDS_Package_Release_of_Application_Software_Month_Appl_ReadData, operation=DataServices_DDS_Package_Release_Read_DDS_Package_Release_of_Application_Software_Month_Appl.ReadData
        OIT_Runnable_DataServices_DDS_Package_Release_Read_DDS_Package_Release_of_Application_Software_Year_Appl_ConditionCheckRead: start-on-event=DataServices_DDS_Package_Release_Read_DDS_Package_Release_of_Application_Software_Year_Appl_ConditionCheckRead, operation=DataServices_DDS_Package_Release_Read_DDS_Package_Release_of_Application_Software_Year_Appl.ConditionCheckRead
        OIT_DataServices_DDS_Package_Release_Read_DDS_Package_Release_of_Application_Software_Year_Appl_ReadData_DataServices_DD925E08A1: start-on-event=DataServices_DDS_Package_Release_Read_DDS_Package_Release_of_Application_Software_Year_Appl_ReadData, operation=DataServices_DDS_Package_Release_Read_DDS_Package_Release_of_Application_Software_Year_Appl.ReadData
        OIT_Runnable_DataServices_DDS_Package_Release_Read_DDS_Package_Release_of_Boot_Software_Month_Boot_ConditionCheckRead: start-on-event=DataServices_DDS_Package_Release_Read_DDS_Package_Release_of_Boot_Software_Month_Boot_ConditionCheckRead, operation=DataServices_DDS_Package_Release_Read_DDS_Package_Release_of_Boot_Software_Month_Boot.ConditionCheckRead
        OIT_DataServices_DDS_Package_Release_Read_DDS_Package_Release_of_Boot_Software_Month_Boot_ReadData_DataServices_DDS_Pack4A13354E: start-on-event=DataServices_DDS_Package_Release_Read_DDS_Package_Release_of_Boot_Software_Month_Boot_ReadData, operation=DataServices_DDS_Package_Release_Read_DDS_Package_Release_of_Boot_Software_Month_Boot.ReadData
        OIT_Runnable_DataServices_DDS_Package_Release_Read_DDS_Package_Release_of_Boot_Software_Year_Boot_ConditionCheckRead: start-on-event=DataServices_DDS_Package_Release_Read_DDS_Package_Release_of_Boot_Software_Year_Boot_ConditionCheckRead, operation=DataServices_DDS_Package_Release_Read_DDS_Package_Release_of_Boot_Software_Year_Boot.ConditionCheckRead
        OIT_DataServices_DDS_Package_Release_Read_DDS_Package_Release_of_Boot_Software_Year_Boot_ReadData_DataServices_DDS_Packa52A373F2: start-on-event=DataServices_DDS_Package_Release_Read_DDS_Package_Release_of_Boot_Software_Year_Boot_ReadData, operation=DataServices_DDS_Package_Release_Read_DDS_Package_Release_of_Boot_Software_Year_Boot.ReadData
        OIT_Runnable_DataServices_Supported_configuration_mechanisms_Read_Config_mechanisms_ConditionCheckRead: start-on-event=DataServices_Supported_configuration_mechanisms_Read_Config_mechanisms_ConditionCheckRead, operation=DataServices_Supported_configuration_mechanisms_Read_Config_mechanisms.ConditionCheckRead
        OIT_DataServices_Supported_configuration_mechanisms_Read_Config_mechanisms_ReadData_DataServices_Supported_configurationB9F91EFC: start-on-event=DataServices_Supported_configuration_mechanisms_Read_Config_mechanisms_ReadData, operation=DataServices_Supported_configuration_mechanisms_Read_Config_mechanisms.ReadData
        OIT_Runnable_DataServices_Diagnostic_Trace_Memory_Read_Diagnostic_Trace_Memory_ConditionCheckRead: start-on-event=DataServices_Diagnostic_Trace_Memory_Read_Diagnostic_Trace_Memory_ConditionCheckRead, operation=DataServices_Diagnostic_Trace_Memory_Read_Diagnostic_Trace_Memory.ConditionCheckRead
        OIT_DataServices_Diagnostic_Trace_Memory_Read_Diagnostic_Trace_Memory_ReadData_DataServices_Diagnostic_Trace_Memory_Read70CCB86F: start-on-event=DataServices_Diagnostic_Trace_Memory_Read_Diagnostic_Trace_Memory_ReadData, operation=DataServices_Diagnostic_Trace_Memory_Read_Diagnostic_Trace_Memory.ReadData
        OIT_DataServices_Diagnostic_Trace_Memory_Read_Diagnostic_Trace_Memory_WriteData_DataServices_Diagnostic_Trace_Memory_ReaFF4C5B8F: start-on-event=DataServices_Diagnostic_Trace_Memory_Read_Diagnostic_Trace_Memory_WriteData, operation=DataServices_Diagnostic_Trace_Memory_Read_Diagnostic_Trace_Memory.WriteData
        OIT_Runnable_DataServices_Adjust_ISO_15765_2_Block_Size_and_STmin_Parameter_Read_Block_Size_Value_as_defined_in_ISO_15760D74413B: start-on-event=DataServices_Adjust_ISO_15765_2_Block_Size_and_STmin_Parameter_Read_Block_Size_Value_ConditionCheckRead, operation=DataServices_Adjust_ISO_15765_2_Block_Size_and_STmin_Parameter_Read_Block_Size_Value_as_defined_in_ISO_15765_2.ConditionCheckRead
        OIT_DataServices_Adjust_ISO_15765_2_Block_Size_and_STmin_Parameter_Read_Block_Size_Value_ReadData_DataServices_Adjust_ISEB22D14D: start-on-event=DataServices_Adjust_ISO_15765_2_Block_Size_and_STmin_Parameter_Read_Block_Size_Value_ReadData, operation=DataServices_Adjust_ISO_15765_2_Block_Size_and_STmin_Parameter_Read_Block_Size_Value_as_defined_in_ISO_15765_2.ReadData
        OIT_DataServices_Adjust_ISO_15765_2_Block_Size_and_STmin_Parameter_Read_Block_Size_Value_WriteData_DataServices_Adjust_IA602CCB2: start-on-event=DataServices_Adjust_ISO_15765_2_Block_Size_and_STmin_Parameter_Read_Block_Size_Value_WriteData, operation=DataServices_Adjust_ISO_15765_2_Block_Size_and_STmin_Parameter_Read_Block_Size_Value_as_defined_in_ISO_15765_2.WriteData
        OIT_Runnable_DataServices_Adjust_ISO_15765_2_Block_Size_and_STmin_Parameter_Read_STmin_Value_as_defined_in_ISO_15765_2_C32AFCCF2: start-on-event=DataServices_Adjust_ISO_15765_2_Block_Size_and_STmin_Parameter_Read_STmin_Value_ConditionCheckRead, operation=DataServices_Adjust_ISO_15765_2_Block_Size_and_STmin_Parameter_Read_STmin_Value_as_defined_in_ISO_15765_2.ConditionCheckRead
        OIT_DataServices_Adjust_ISO_15765_2_Block_Size_and_STmin_Parameter_Read_STmin_Value_ReadData_DataServices_Adjust_ISO_157D56DE0AB: start-on-event=DataServices_Adjust_ISO_15765_2_Block_Size_and_STmin_Parameter_Read_STmin_Value_ReadData, operation=DataServices_Adjust_ISO_15765_2_Block_Size_and_STmin_Parameter_Read_STmin_Value_as_defined_in_ISO_15765_2.ReadData
        OIT_DataServices_Adjust_ISO_15765_2_Block_Size_and_STmin_Parameter_Read_STmin_Value_WriteData_DataServices_Adjust_ISO_155E5011E7: start-on-event=DataServices_Adjust_ISO_15765_2_Block_Size_and_STmin_Parameter_Read_STmin_Value_WriteData, operation=DataServices_Adjust_ISO_15765_2_Block_Size_and_STmin_Parameter_Read_STmin_Value_as_defined_in_ISO_15765_2.WriteData
        OIT_Runnable_DataServices_Reprogramming_Attempt_Counter_Read_Reprogramming_Attempts_ConditionCheckRead: start-on-event=DataServices_Reprogramming_Attempt_Counter_Read_Reprogramming_Attempts_ConditionCheckRead, operation=DataServices_Reprogramming_Attempt_Counter_Read_Reprogramming_Attempts.ConditionCheckRead
        OIT_DataServices_Reprogramming_Attempt_Counter_Read_Reprogramming_Attempts_ReadData_DataServices_Reprogramming_Attempt_C4F79351F: start-on-event=DataServices_Reprogramming_Attempt_Counter_Read_Reprogramming_Attempts_ReadData, operation=DataServices_Reprogramming_Attempt_Counter_Read_Reprogramming_Attempts.ReadData
        OIT_DataServices_Reprogramming_Attempt_Counter_Read_Reprogramming_Attempts_ReadDataLength_DataServices_Reprogramming_Att742EB2AD: start-on-event=DataServices_Reprogramming_Attempt_Counter_Read_Reprogramming_Attempts_ReadDataLength, operation=DataServices_Reprogramming_Attempt_Counter_Read_Reprogramming_Attempts.ReadDataLength
      init event DiagFunction_InitEvent: start-on-event=DiagFunction_Init
      11 x operation invoked event:
        OIT_DataServices_PreCheck_Programming_Dependencies_RoutineServices_Routine_PreCheckProgrammingDependencies_Start_Start: start-on-event=DataServices_PreCheckProgrammingDependencies_Start, operation=RoutineServices_Routine_PreCheckProgrammingDependencies_Start.Start
        OIT_Runnable_RoutineServices_Routine_Synchronize_to_Non_volatile_Memory_Start_Start: start-on-event=DataServices_Synchronize_to_Non_volatile_Memory_Start, operation=RoutineServices_Routine_Synchronize_to_Non_volatile_Memory_Start.Start
        OIT_Synchronize_to_Non_volatile_Memory_Stop_RoutineServices_Routine_Synchronize_to_Non_volatile_Memory_Start_Stop: start-on-event=Synchronize_to_Non_volatile_Memory_Stop, operation=RoutineServices_Routine_Synchronize_to_Non_volatile_Memory_Start.Stop
        OIT_Synchronize_to_Non_volatile_Memory_RequestResults_RoutineServices_Routine_Synchronize_to_Non_volatile_Memory_Start_RF98D2247: start-on-event=Synchronize_to_Non_volatile_Memory_RequestResults, operation=RoutineServices_Routine_Synchronize_to_Non_volatile_Memory_Start.RequestResults
        OIT_StbM_MeasurementNotification_GTD_BODY3_0_14e64f11_SyncTimeRecordBlock_StbM_MeasurementNotification_GTD_BODY3_0_14e6409232DEB: start-on-event=DiagFunction_StbM_MeasurementNotification_GTD_BODY3_0_14e64f11_SyncTimeRecordBlock, operation=StbM_MeasurementNotification_GTD_BODY3_0_14e64f11.SyncTimeRecordBlock
        OIT_Runnable_DataServices_Standard_Application_SW_Package_Information_Read_AUTOSAR_Platform_ConditionCheckRead: start-on-event=DataServices_Standard_Application_SW_Package_Information_Read_AUTOSAR_Platform_ConditionCheckRead, operation=DataServices_Standard_Application_SW_Package_Information_Read_AUTOSAR_Platform.ConditionCheckRead
        OIT_Runnable_DataServices_Standard_Application_SW_Package_Information_Read_AUTOSAR_Platform_ReadData: start-on-event=DataServices_Standard_Application_SW_Package_Information_Read_AUTOSAR_Platform_ReadData, operation=DataServices_Standard_Application_SW_Package_Information_Read_AUTOSAR_Platform.ReadData
        OIT_RoELight_DTCStatusChanged_Callback_CallbackDTCStatusChange_DTCStatusChanged: start-on-event=RoELight_DTCStatusChanged_Callback, operation=CallbackDTCStatusChange.DTCStatusChanged
        OIT_DataServices_Global_Time_Sync_Measured_Values_ConditionCheckRead_DataServices_Global_Time_Sync_Measured_Values_Read_49B9019A: start-on-event=DataServices_Global_Time_Sync_Measured_Values_ConditionCheckRead, operation=DataServices_Global_Time_Sync_Measured_Values_Read_GTSM.ConditionCheckRead
        OIT_DataServices_Global_Time_Sync_Measured_Values_ReadData_DataServices_Global_Time_Sync_Measured_Values_Read_GTSM_ReadData: start-on-event=DataServices_Global_Time_Sync_Measured_Values_ReadData, operation=DataServices_Global_Time_Sync_Measured_Values_Read_GTSM.ReadData
        OIT_DataServices_Global_Time_Sync_Measured_Values_ReadDataLength_DataServices_Global_Time_Sync_Measured_Values_Read_GTSMB9839A97: start-on-event=DataServices_Global_Time_Sync_Measured_Values_ReadDataLength, operation=DataServices_Global_Time_Sync_Measured_Values_Read_GTSM.ReadDataLength
      data received event DRT_RoELite_SecureEventNotification_R_Sec_Event_ST3_Data: start-on-event=RoELite_SecureEventNotification, data=R_Sec_Event_ST3.Data
      data received event DRT_RoELite_AvailabilityDataHandler_R_AvailabilityDataHandler_AvailabilityDataCategory: start-on-event=RoELite_AvailabilityDataHandler, data=R_AvailabilityDataHandler.AvailabilityDataCategory
      data received event DRT_RoELite_ObsolescenceDataHandler_ObsolescenceDataBlockNumber_BlockNumber: start-on-event=RoELite_ObsolescenceDataHandler, data=ObsolescenceDataBlockNumber.BlockNumber
      38 x operation invoked event:
        OIT_Snapshot_DataServices_Data_DID_0x10a_Vehicle_Odometer_in_Low_Resolution_Snapshot_DataServices_Data_DID_0x10a_Vehicle0036DF48: start-on-event=Snapshot_DataServices_Data_DID_0x10a_Vehicle_Odometer_in_Low_Resolution, operation=Snapshot_DataServices_Data_DID_0x10a_Vehicle_Odometer_in_Low_Resolution.ReadData
        OIT_Snapshot_DataServices_Data_DID_0x133_Current_Operating_Time_Snapshot_DataServices_Data_DID_0x133_Current_Operating_T350192C4: start-on-event=Snapshot_DataServices_Data_DID_0x133_Current_Operating_Time, operation=Snapshot_DataServices_Data_DID_0x133_Current_Operating_Time.ReadData
        OIT_DiagFunction_runReadGlobalTime_pseSystemTime_ReadAbsoluteSystemTime: start-on-event=DiagFunction_runReadGlobalTime, operation=pseSystemTime.ReadAbsoluteSystemTime
        OIT_Runnable_DataServices_HSM_Identification_Read_HSM_MB_Partnumber_ConditionCheckRead: start-on-event=DataServices_HSM_Identification_Read_HSM_MB_Partnumber_ConditionCheckRead, operation=DataServices_HSM_Identification_Read_HSM_MB_Partnumber.ConditionCheckRead
        OIT_Runnable_DataServices_HSM_Identification_Read_HSM_MB_Partnumber_ReadData: start-on-event=DataServices_HSM_Identification_Read_HSM_MB_Partnumber_ReadData, operation=DataServices_HSM_Identification_Read_HSM_MB_Partnumber.ReadData
        OIT_Runnable_DataServices_HSM_Identification_Read_HSM_MB_Supplier_Version_HW_patch_level_ConditionCheckRead: start-on-event=DataServices_HSM_Identification_Read_HSM_MB_Supplier_Version_HW_patch_level_ConditionCheckRead, operation=DataServices_HSM_Identification_Read_HSM_MB_Supplier_Version_HW_patch_level.ConditionCheckRead
        OIT_Runnable_DataServices_HSM_Identification_Read_HSM_MB_Supplier_Version_HW_patch_level_ReadData: start-on-event=DataServices_HSM_Identification_Read_HSM_MB_Supplier_Version_HW_patch_level_ReadData, operation=DataServices_HSM_Identification_Read_HSM_MB_Supplier_Version_HW_patch_level.ReadData
        OIT_Runnable_1_DataServices_HSM_Identification_Read_HSM_MB_Supplier_Version_HW_week_ConditionCheckRead: start-on-event=DataServices_HSM_Identification_Read_HSM_MB_Supplier_Version_HW_week_ConditionCheckRead, operation=DataServices_HSM_Identification_Read_HSM_MB_Supplier_Version_HW_week.ConditionCheckRead
        OIT_Runnable_DataServices_HSM_Identification_Read_HSM_MB_Supplier_Version_HW_week_ReadData: start-on-event=DataServices_HSM_Identification_Read_HSM_MB_Supplier_Version_HW_week_ReadData, operation=DataServices_HSM_Identification_Read_HSM_MB_Supplier_Version_HW_week.ReadData
        OIT_Runnable_DataServices_HSM_Identification_Read_HSM_MB_Supplier_Version_HW_year_ConditionCheckRead: start-on-event=DataServices_HSM_Identification_Read_HSM_MB_Supplier_Version_HW_year_ConditionCheckRead, operation=DataServices_HSM_Identification_Read_HSM_MB_Supplier_Version_HW_year.ConditionCheckRead
        OIT_Runnable_DataServices_HSM_Identification_Read_HSM_MB_Supplier_Version_HW_year_ReadData: start-on-event=DataServices_HSM_Identification_Read_HSM_MB_Supplier_Version_HW_year_ReadData, operation=DataServices_HSM_Identification_Read_HSM_MB_Supplier_Version_HW_year.ReadData
        OIT_Runnable_DataServices_HSM_Identification_Read_HSM_MB_Version_HW_patch_level_ConditionCheckRead: start-on-event=DataServices_HSM_Identification_Read_HSM_MB_Version_HW_patch_level_ConditionCheckRead, operation=DataServices_HSM_Identification_Read_HSM_MB_Version_HW_patch_level.ConditionCheckRead
        OIT_Runnable_DataServices_HSM_Identification_Read_HSM_MB_Version_HW_patch_level_ReadData: start-on-event=DataServices_HSM_Identification_Read_HSM_MB_Version_HW_patch_level_ReadData, operation=DataServices_HSM_Identification_Read_HSM_MB_Version_HW_patch_level.ReadData
        OIT_Runnable_DataServices_HSM_Identification_Read_HSM_MB_Version_HW_week_ConditionCheckRead: start-on-event=DataServices_HSM_Identification_Read_HSM_MB_Version_HW_week_ConditionCheckRead, operation=DataServices_HSM_Identification_Read_HSM_MB_Version_HW_week.ConditionCheckRead
        OIT_Runnable_DataServices_HSM_Identification_Read_HSM_MB_Version_HW_week_ReadData: start-on-event=DataServices_HSM_Identification_Read_HSM_MB_Version_HW_week_ReadData, operation=DataServices_HSM_Identification_Read_HSM_MB_Version_HW_week.ReadData
        OIT_Runnable_DataServices_HSM_Identification_Read_HSM_MB_Version_HW_year_ConditionCheckRead: start-on-event=DataServices_HSM_Identification_Read_HSM_MB_Version_HW_year_ConditionCheckRead, operation=DataServices_HSM_Identification_Read_HSM_MB_Version_HW_year.ConditionCheckRead
        OIT_Runnable_DataServices_HSM_Identification_Read_HSM_MB_Version_HW_year_ReadData: start-on-event=DataServices_HSM_Identification_Read_HSM_MB_Version_HW_year_ReadData, operation=DataServices_HSM_Identification_Read_HSM_MB_Version_HW_year.ReadData
        OIT_Runnable_DataServices_HSM_Identification_Read_HSM_MB_Partnumber_WriteData: start-on-event=DataServices_HSM_Identification_Read_HSM_MB_Partnumber_WriteData, operation=DataServices_HSM_Identification_Read_HSM_MB_Partnumber.WriteData
        OIT_Runnable_DataServices_HSM_Identification_Read_HSM_MB_Supplier_Version_HW_patch_level_WriteData: start-on-event=DataServices_HSM_Identification_Read_HSM_MB_Supplier_Version_HW_patch_level_WriteData, operation=DataServices_HSM_Identification_Read_HSM_MB_Supplier_Version_HW_patch_level.WriteData
        OIT_Runnable_DataServices_HSM_Identification_Read_HSM_MB_Supplier_Version_HW_week_WriteData: start-on-event=DataServices_HSM_Identification_Read_HSM_MB_Supplier_Version_HW_week_WriteData, operation=DataServices_HSM_Identification_Read_HSM_MB_Supplier_Version_HW_week.WriteData
        OIT_Runnable_DataServices_HSM_Identification_Read_HSM_MB_Supplier_Version_HW_year_WriteData: start-on-event=DataServices_HSM_Identification_Read_HSM_MB_Supplier_Version_HW_year_WriteData, operation=DataServices_HSM_Identification_Read_HSM_MB_Supplier_Version_HW_year.WriteData
        OIT_Runnable_DataServices_HSM_Identification_Read_HSM_MB_Version_HW_patch_level_WriteData: start-on-event=DataServices_HSM_Identification_Read_HSM_MB_Version_HW_patch_level_WriteData, operation=DataServices_HSM_Identification_Read_HSM_MB_Version_HW_patch_level.WriteData
        OIT_Runnable_DataServices_HSM_Identification_Read_HSM_MB_Version_HW_week_WriteData: start-on-event=DataServices_HSM_Identification_Read_HSM_MB_Version_HW_week_WriteData, operation=DataServices_HSM_Identification_Read_HSM_MB_Version_HW_week.WriteData
        OIT_Runnable_DataServices_HSM_Identification_Read_HSM_MB_Version_HW_year_WriteData: start-on-event=DataServices_HSM_Identification_Read_HSM_MB_Version_HW_year_WriteData, operation=DataServices_HSM_Identification_Read_HSM_MB_Version_HW_year.WriteData
        OIT_DataServices_Standard_Application_SW_Package_Information_Read_C_P_Identification_ConditionCheckRead_DataServices_StaFA6D623A: start-on-event=DataServices_Standard_Application_SW_Package_Information_Read_C_P_Identification_ConditionCheckRead, operation=DataServices_Standard_Application_SW_Package_Information_Read_C_P_Identification.ConditionCheckRead
        OIT_DataServices_Standard_Application_SW_Package_Information_Read_C_P_Identification_ReadData_DataServices_Standard_ApplBDD8F85C: start-on-event=DataServices_Standard_Application_SW_Package_Information_Read_C_P_Identification_ReadData, operation=DataServices_Standard_Application_SW_Package_Information_Read_C_P_Identification.ReadData
        OIT_Runnable_DataServices_MercedesCarGroupSoftware_Read_Software_Logical_Block_Numbers_ReadDataLength: start-on-event=DataServices_MercedesCarGroupHardware_Read_Software_Part_Number_ReadDataLength, operation=DataServices_MercedesCarGroupSoftware_Read_Software_Logical_Block_Numbers.ReadDataLength
        OIT_DataServices_Customer_Settings_Read_BltSlckDec_Md_Stat_DataServices_Customer_Settings_Read_BltSlckDec_Md_Stat_Condit454F76C7: start-on-event=DataServices_Customer_Settings_Read_BltSlckDec_Md_Stat_ConditionCheckRead, operation=DataServices_Customer_Settings_Read_BltSlckDec_Md_Stat.ConditionCheckRead
        OIT_DataServices_Customer_Settings_Read_BltSlckDec_Md_Stat_ReadData_DataServices_Customer_Settings_Read_BltSlckDec_Md_St65CE77EE: start-on-event=DataServices_Customer_Settings_Read_BltSlckDec_Md_Stat_ReadData, operation=DataServices_Customer_Settings_Read_BltSlckDec_Md_Stat.ReadData
        OIT_DataServices_Customer_Settings_Read_PS_Curve_Stat_ConditionCheckRead_DataServices_Customer_Settings_Read_PS_Curve_St056AD58A: start-on-event=DataServices_Customer_Settings_Read_PS_Curve_Stat_ConditionCheckRead, operation=DataServices_Customer_Settings_Read_PS_Curve_Stat.ConditionCheckRead
        OIT_DataServices_Customer_Settings_Read_PS_Curve_Stat_ReadData_DataServices_Customer_Settings_Read_PS_Curve_Stat_ReadData: start-on-event=DataServices_Customer_Settings_Read_PS_Curve_Stat_ReadData, operation=DataServices_Customer_Settings_Read_PS_Curve_Stat.ReadData
        OIT_DataServices_Trust_Model_CSR_Supplier_Signature_Read_Trust_Model_CSR_Supplier_Signature_ConditionCheckRead_DataServiF043D8A7: start-on-event=DataServices_Trust_Model_CSR_Supplier_Signature_Read_Trust_Model_CSR_Supplier_Signature_ConditionCheckRead, operation=DataServices_Trust_Model_CSR_Supplier_Signature_Read_Trust_Model_CSR_Supplier_Signature.ConditionCheckRead
        OIT_DataServices_Trust_Model_CSR_Supplier_Signature_Read_Trust_Model_CSR_Supplier_Signature_ReadData_DataServices_Trust_CA5411C2: start-on-event=DataServices_Trust_Model_CSR_Supplier_Signature_Read_Trust_Model_CSR_Supplier_Signature_ReadData, operation=DataServices_Trust_Model_CSR_Supplier_Signature_Read_Trust_Model_CSR_Supplier_Signature.ReadData
        OIT_DataServices_Trust_Model_CSR_Supplier_Signature_Read_Trust_Model_CSR_Supplier_Signature_ReadDataLength_DataServices_2A5A172C: start-on-event=DataServices_Trust_Model_CSR_Supplier_Signature_Read_Trust_Model_CSR_Supplier_Signature_ReadDataLength, operation=DataServices_Trust_Model_CSR_Supplier_Signature_Read_Trust_Model_CSR_Supplier_Signature.ReadDataLength
        OIT_DataServices_Trust_Model_CSR_Supplier_Signature_Read_Trust_Model_CSR_Supplier_Signature_WriteData_DataServices_TrustEDCF4793: start-on-event=DataServices_Trust_Model_CSR_Supplier_Signature_Read_Trust_Model_CSR_Supplier_Signature_WriteData, operation=DataServices_Trust_Model_CSR_Supplier_Signature_Read_Trust_Model_CSR_Supplier_Signature.WriteData
        OIT_RoutineServices_Routine_Erase_All_Start_RoutineServices_Routine_Erase_All_Start_Start: start-on-event=RoutineServices_Routine_Erase_All_Start, operation=RoutineServices_Routine_Erase_All_Start.Start
        OIT_RoutineServices_Routine_Force_External_WDG_Start_RoutineServices_Routine_Force_External_WDG_Start_Start: start-on-event=RoutineServices_Routine_Force_External_WDG_Start, operation=RoutineServices_Routine_Force_External_WDG_Start.Start
        OIT_Snapshot_DataServices_Data_DID_0xfd05_Root_Causes_Snapshot_DataServices_Data_DID_0xfd05_Root_Causes_ReadData: start-on-event=Snapshot_DataServices_Data_DID_0xfd05_Root_Causes, operation=Snapshot_DataServices_Data_DID_0xfd05_Root_Causes.ReadData
      timing event TMT_DiagFunction_MainFunction: start-on-event=DiagFunction_MainFunction, period=0.02
      152 x runnable:
        DataServices_ActiveDiagnosticInformation_Read_Identification_ReadData
        DataServices_HardwareSupplier_Read_Hardware_Supplier_Identification_ConditionCheckRead
        DataServices_HardwareVersion_Read_HW_year_ConditionCheckRead
        DataServices_MercedesCarGroupHardware_Read_Hardware_Part_Number_ConditionCheckRead
        DataServices_ActiveDiagnosticInformation_Read_Session_ReadData
          sync call SC_DCMServices_GetSesCtrlType: operation=DCMServices.GetSesCtrlType
        DataServices_SoftwareSupplier_Read_Software_Logical_Block_Supplier_Identification_ReadData
        DataServices_SoftwareVersion_Read_Software_Logical_Block_Version_Information_ReadData
        DataServices_SoftwareVersion_Read_Software_Logical_Block_Version_Information_ReadDataLength
        DataServices_SoftwareVersion_Read_Software_Logical_Block_Version_Information_ConditionCheckRead
        DataServices_SoftwareSupplier_Read_Software_Logical_Block_Supplier_Identification_ReadDataLength
        DataServices_SoftwareSupplier_Read_Software_Logical_Block_Supplier_Identification_ConditionCheckRead
        DataServices_HardwareVersion_Read_HW_year_ReadData
        DataServices_MercedesCarGroupHardware_Read_Hardware_Part_Number_ReadData
        DataServices_BootSoftwareVersion_Read_Boot_SW_year_ConditionCheckRead
        DataServices_BootSoftwareVersion_Read_Boot_SW_year_ReadData
        DataServices_MercedesCarGroupHardware_Read_Software_Part_Number_ConditionCheckRead
        DataServices_MercedesCarGroupHardware_Read_Software_Part_Number_ReadData
        DataServices_ActiveDiagnosticInformation_Read_Identification_ConditionCheckRead
        DataServices_ActiveDiagnosticInformation_Read_Session_ConditionCheckRead
        DataServices_HardwareSupplier_Read_Hardware_Supplier_Identification_ReadData
        DataServices_HardwareVersion_Read_HW_week_ConditionCheckRead
        DataServices_HardwareVersion_Read_HW_patch_level_ConditionCheckRead
        DataServices_HardwareVersion_Read_HW_week_ReadData
        DataServices_HardwareVersion_Read_HW_patch_level_ReadData
        DataServices_BootSoftwareVersion_Read_Boot_SW_week_ConditionCheckRead
        DataServices_BootSoftwareVersion_Read_Boot_SW_patch_level_ConditionCheckRead
        DataServices_BootSoftwareVersion_Read_Boot_SW_week_ReadData
        DataServices_BootSoftwareVersion_Read_Boot_SW_patch_level_ReadData
        DataServices_Vehicle_Odometer_in_Low_Resolution_Read_Vehicle_Odometer_in_Low_Resolution_ConditionCheckRead
        DataServices_Vehicle_Odometer_in_Low_Resolution_Read_Vehicle_Odometer_in_Low_Resolution_ReadData
          data-receive-point-by-arguments:
            access REC_R_DI_Odo_Pr5_ST3_DI_Odo_Pr5_ST3: accessed-variable=R_DI_Odo_Pr5_ST3.DI_Odo_Pr5_ST3
        DataServices_Current_Operating_Time_Read_Current_Operating_Time_ConditionCheckRead
        DataServices_Current_Operating_Time_Read_Current_Operating_Time_ReadData
          sync call SC_GlobalTime_Slave_GTD_BODY3_0_14e64f11_GetCurrentTime: operation=GlobalTime_Slave_GTD_BODY3_0_14e64f11.GetCurrentTime
        DataServices_Current_Operating_Time_Read_Operating_Time_Status_ConditionCheckRead
        DataServices_Current_Operating_Time_Read_Operating_Time_Status_ReadData
          sync call SC_GlobalTime_Slave_GTD_BODY3_0_14e64f11_GetCurrentTime: operation=GlobalTime_Slave_GTD_BODY3_0_14e64f11.GetCurrentTime
        DataServices_BSR_Counter_read_Read_BSR_Counter_ConditionCheckRead
        DataServices_BSR_Counter_read_Read_BSR_Counter_ReadData
        DataServices_PRE_SAFE_Counter_read_Read_CombinedDataElement_ConditionCheckRead
        DataServices_PRE_SAFE_Counter_read_Read_CombinedDataElement_ReadData
        DataServices_PRE_SAFE_Counter_read_Read_CombinedDataElement_ReadDataLength
        DataServices_PRE_SAFE_Counter_read_Read_CombinedDataElement_WriteData
          sync call SC_NvMService_Execution_Counters_SetRamBlockStatus: operation=NvMService_Execution_Counters.SetRamBlockStatus
        DataServices_System_Time_read_Read_System_time_ConditionCheckRead
        DataServices_System_Time_read_Read_System_time_ReadData
          sync call SC_GlobalTime_Slave_GTD_BODY3_0_14e64f11_GetCurrentTime: operation=GlobalTime_Slave_GTD_BODY3_0_14e64f11.GetCurrentTime
        DataServices_ReadFingerprint_Read_Software_Fingerprint_s_ConditionCheckRead
        DataServices_ReadFingerprint_Read_Software_Fingerprint_s_ReadData
        DataServices_ReadFingerprint_Read_Software_Fingerprint_s_ReadDataLength
        DataServices_ECU_Name_Read_Diagnostic_ECU_Name_ConditionCheckRead
        DataServices_ECU_Name_Read_Diagnostic_ECU_Name_ReadData
        DataServices_ECU_Name_Read_Diagnostic_ECU_Name_ReadDataLength
        DataServices_Diagnostic_Extract_Version_Read_CANdela_Version_ConditionCheckRead
        DataServices_Diagnostic_Extract_Version_Read_CANdela_Version_ReadData
        DataServices_Diagnostic_Extract_Version_Read_DDM_Version_ConditionCheckRead
        DataServices_Diagnostic_Extract_Version_Read_DDM_Version_ReadData
        DataServices_Diagnostic_Extract_Version_Read_Diagnostic_Extract_Major_Version_ConditionCheckRead
        DataServices_Diagnostic_Extract_Version_Read_Diagnostic_Extract_Major_Version_ReadData
        DataServices_Diagnostic_Extract_Version_Read_Diagnostic_Extract_Minor_Version_ConditionCheckRead
        DataServices_Diagnostic_Extract_Version_Read_Diagnostic_Extract_Minor_Version_ReadData
        DataServices_Diagnostic_Extract_Version_Read_Diagnostic_Extract_Patch_Version_ConditionCheckRead
        DataServices_Diagnostic_Extract_Version_Read_Diagnostic_Extract_Patch_Version_ReadData
        DataServices_Diagnostic_Extract_Version_Read_Exported_Diagnostic_Variant_ConditionCheckRead
        DataServices_Diagnostic_Extract_Version_Read_Exported_Diagnostic_Variant_ReadData
        DataServices_Minimum_Software_Version_Read_Minimum_Software_Version_ConditionCheckRead
        DataServices_Minimum_Software_Version_Read_Minimum_Software_Version_ReadData
        DataServices_Minimum_Software_Version_Read_Minimum_Software_Version_ReadDataLength
        DataServices_Standard_Application_SW_Package_Information_Read_C_P_Identification_ConditionCheckRead
        DataServices_Standard_Application_SW_Package_Information_Read_C_P_Identification_ReadData
        DataServices_Standard_Application_SW_Package_Information_Read_Standard_Application_SW_Package_Build_Version_ConditionCheckRead
        DataServices_Standard_Application_SW_Package_Information_Read_Standard_Application_SW_Package_Build_Version_ReadData
        DataServices_Standard_Application_SW_Package_Information_Read_Standard_Application_SW_Package_Major_Version_ConditionCheckRead
        DataServices_Standard_Application_SW_Package_Information_Read_Standard_Application_SW_Package_Major_Version_ReadData
        DataServices_Standard_Application_SW_Package_Information_Read_Standard_Application_SW_Package_Minor_Version_ConditionCheckRead
        DataServices_Standard_Application_SW_Package_Information_Read_Standard_Application_SW_Package_Minor_Version_ReadData
        DataServices_Standard_Application_SW_Package_Information_Read_Standard_Application_SW_Package_Patch_Level_ConditionCheckRead
        DataServices_Standard_Application_SW_Package_Information_Read_Standard_Application_SW_Package_Patch_Level_ReadData
        DataServices_Standard_Application_SW_Package_Information_Read_Supplier_Identification_ConditionCheckRead
        DataServices_Standard_Application_SW_Package_Information_Read_Supplier_Identification_ReadData
        DataServices_Dump_of_Vedoc_Relevant_Information_Read_PatchedObject_ConditionCheckRead: can-be-invoked-concurrently=true
        DataServices_Dump_of_Vedoc_Relevant_Information_Read_PatchedObject_ReadData: can-be-invoked-concurrently=true
        DataServices_Dump_of_Vedoc_Relevant_Information_Read_PatchedObject_ReadDataLength: can-be-invoked-concurrently=true
        DataServices_DDS_Package_Release_Read_DDS_Package_Release_of_Application_Software_Month_Appl_ConditionCheckRead
        DataServices_DDS_Package_Release_Read_DDS_Package_Release_of_Application_Software_Month_Appl_ReadData
        DataServices_DDS_Package_Release_Read_DDS_Package_Release_of_Application_Software_Year_Appl_ConditionCheckRead
        DataServices_DDS_Package_Release_Read_DDS_Package_Release_of_Application_Software_Year_Appl_ReadData
        DataServices_DDS_Package_Release_Read_DDS_Package_Release_of_Boot_Software_Month_Boot_ConditionCheckRead
        DataServices_DDS_Package_Release_Read_DDS_Package_Release_of_Boot_Software_Month_Boot_ReadData
        DataServices_DDS_Package_Release_Read_DDS_Package_Release_of_Boot_Software_Year_Boot_ConditionCheckRead
        DataServices_DDS_Package_Release_Read_DDS_Package_Release_of_Boot_Software_Year_Boot_ReadData
        DataServices_Supported_configuration_mechanisms_Read_Config_mechanisms_ConditionCheckRead
        DataServices_Supported_configuration_mechanisms_Read_Config_mechanisms_ReadData
        DataServices_Diagnostic_Trace_Memory_Read_Diagnostic_Trace_Memory_ConditionCheckRead
        DataServices_Diagnostic_Trace_Memory_Read_Diagnostic_Trace_Memory_ReadData
        DataServices_Diagnostic_Trace_Memory_Read_Diagnostic_Trace_Memory_WriteData
        DataServices_Adjust_ISO_15765_2_Block_Size_and_STmin_Parameter_Read_Block_Size_Value_ConditionCheckRead
        DataServices_Adjust_ISO_15765_2_Block_Size_and_STmin_Parameter_Read_Block_Size_Value_ReadData
        DataServices_Adjust_ISO_15765_2_Block_Size_and_STmin_Parameter_Read_Block_Size_Value_WriteData
        DataServices_Adjust_ISO_15765_2_Block_Size_and_STmin_Parameter_Read_STmin_Value_ConditionCheckRead
        DataServices_Adjust_ISO_15765_2_Block_Size_and_STmin_Parameter_Read_STmin_Value_ReadData
        DataServices_Adjust_ISO_15765_2_Block_Size_and_STmin_Parameter_Read_STmin_Value_WriteData
        DataServices_Global_Time_Sync_Measured_Values_ConditionCheckRead
        DataServices_Global_Time_Sync_Measured_Values_ReadData
        DataServices_Reprogramming_Attempt_Counter_Read_Reprogramming_Attempts_ConditionCheckRead
        DataServices_Reprogramming_Attempt_Counter_Read_Reprogramming_Attempts_ReadData
        DataServices_Reprogramming_Attempt_Counter_Read_Reprogramming_Attempts_ReadDataLength
        DiagFunction_Init
          5 x sync call:
            SC_NvMService_FblTransferedMetadata_GetErrorStatus: operation=NvMService_FblMetaData.GetErrorStatus
            SC_NvMService_FblTransferedMetadata_ReadBlock: operation=NvMService_FblMetaData.ReadBlock
            SC_NvMService_FblTransferedMetadata_SetDataIndex: operation=NvMService_FblMetaData.SetDataIndex
            SC_NvMService_HW_Partnumber_GetErrorStatus: operation=NvMService_HW_Partnumber.GetErrorStatus
            SC_NvMService_HW_Partnumber_ReadBlock: operation=NvMService_HW_Partnumber.ReadBlock
        DataServices_PreCheckProgrammingDependencies_Start
        DataServices_Synchronize_to_Non_volatile_Memory_Start
        Synchronize_to_Non_volatile_Memory_Stop
        Synchronize_to_Non_volatile_Memory_RequestResults
        DiagFunction_StbM_MeasurementNotification_GTD_BODY3_0_14e64f11_SyncTimeRecordBlock
        DataServices_Standard_Application_SW_Package_Information_Read_AUTOSAR_Platform_ConditionCheckRead
        DataServices_Standard_Application_SW_Package_Information_Read_AUTOSAR_Platform_ReadData
        RoELight_DTCStatusChanged_Callback: can-enter-exclusive-area=DiagFunction_ExclusiveArea
          data-send-points:
            access SEND_P_ROE_ROE_XX_ST3: accessed-variable=P_ROE.ROE_XX_ST3
        DataServices_Global_Time_Sync_Measured_Values_ReadDataLength
        RoELite_SecureEventNotification: can-enter-exclusive-area=DiagFunction_ExclusiveArea
          data-receive-point-by-arguments:
            access REC_R_Sec_Event_ST3_Data: accessed-variable=R_Sec_Event_ST3.Data
        RoELite_AvailabilityDataHandler: can-enter-exclusive-area=DiagFunction_ExclusiveArea
          data-receive-point-by-arguments:
            access REC_R_AvailabilityDataHandler_AvailabilityDataCategory: accessed-variable=R_AvailabilityDataHandler.AvailabilityDataCategory
          data-send-points:
            access SEND_P_ROE_ROE_XX_ST3: accessed-variable=P_ROE.ROE_XX_ST3
        RoELite_ObsolescenceDataHandler: can-enter-exclusive-area=DiagFunction_ExclusiveArea
          data-receive-point-by-arguments:
            access REC_ObsolescenceDataBlockNumber_BlockNumber: accessed-variable=ObsolescenceDataBlockNumber.BlockNumber
          data-send-points:
            access SEND_P_ROE_ROE_XX_ST3: accessed-variable=P_ROE.ROE_XX_ST3
          sync call SC_If_Obsolescence_Data_Get_Data: operation=If_Obsolescence_Data.Get_Data
        Snapshot_DataServices_Data_DID_0x10a_Vehicle_Odometer_in_Low_Resolution
        Snapshot_DataServices_Data_DID_0x133_Current_Operating_Time
        DiagFunction_runReadGlobalTime
        DataServices_HSM_Identification_Read_HSM_MB_Partnumber_ConditionCheckRead
        DataServices_HSM_Identification_Read_HSM_MB_Partnumber_ReadData
        DataServices_HSM_Identification_Read_HSM_MB_Supplier_Version_HW_patch_level_ConditionCheckRead
        DataServices_HSM_Identification_Read_HSM_MB_Supplier_Version_HW_patch_level_ReadData
        DataServices_HSM_Identification_Read_HSM_MB_Supplier_Version_HW_week_ConditionCheckRead
        DataServices_HSM_Identification_Read_HSM_MB_Supplier_Version_HW_week_ReadData
        DataServices_HSM_Identification_Read_HSM_MB_Supplier_Version_HW_year_ConditionCheckRead
        DataServices_HSM_Identification_Read_HSM_MB_Supplier_Version_HW_year_ReadData
        DataServices_HSM_Identification_Read_HSM_MB_Version_HW_patch_level_ConditionCheckRead
        DataServices_HSM_Identification_Read_HSM_MB_Version_HW_patch_level_ReadData
        DataServices_HSM_Identification_Read_HSM_MB_Version_HW_week_ConditionCheckRead
        DataServices_HSM_Identification_Read_HSM_MB_Version_HW_week_ReadData
        DataServices_HSM_Identification_Read_HSM_MB_Version_HW_year_ConditionCheckRead
        DataServices_HSM_Identification_Read_HSM_MB_Version_HW_year_ReadData
        DataServices_HSM_Identification_Read_HSM_MB_Partnumber_WriteData
        DataServices_HSM_Identification_Read_HSM_MB_Supplier_Version_HW_patch_level_WriteData
        DataServices_HSM_Identification_Read_HSM_MB_Supplier_Version_HW_week_WriteData
        DataServices_HSM_Identification_Read_HSM_MB_Supplier_Version_HW_year_WriteData
        DataServices_HSM_Identification_Read_HSM_MB_Version_HW_patch_level_WriteData
        DataServices_HSM_Identification_Read_HSM_MB_Version_HW_week_WriteData
        DataServices_HSM_Identification_Read_HSM_MB_Version_HW_year_WriteData
        DataServices_MercedesCarGroupHardware_Read_Software_Part_Number_ReadDataLength
        DataServices_Customer_Settings_Read_BltSlckDec_Md_Stat_ConditionCheckRead
        DataServices_Customer_Settings_Read_BltSlckDec_Md_Stat_ReadData
          data-receive-point-by-arguments:
            access REC_R_BltSlckDec_Md_XX_Stat_ST3_BltSlckDec_Md_XX_Stat_ST3: accessed-variable=R_BltSlckDec_Md_XX_Stat_ST3.BltSlckDec_Md_XX_Stat_ST3
        DataServices_Customer_Settings_Read_PS_Curve_Stat_ConditionCheckRead
        DataServices_Customer_Settings_Read_PS_Curve_Stat_ReadData
          data-receive-point-by-arguments:
            access REC_R_PS_Curve_FL_Stat_ST3_PS_Curve_FL_Stat_ST3: accessed-variable=R_PS_Curve_FL_Stat_ST3.PS_Curve_FL_Stat_ST3
            access REC_R_PS_Curve_FR_Stat_ST3_PS_Curve_FR_Stat_ST3: accessed-variable=R_PS_Curve_FR_Stat_ST3.PS_Curve_FR_Stat_ST3
        DataServices_Trust_Model_CSR_Supplier_Signature_Read_Trust_Model_CSR_Supplier_Signature_ConditionCheckRead
        DataServices_Trust_Model_CSR_Supplier_Signature_Read_Trust_Model_CSR_Supplier_Signature_ReadData
          sync call SC_NvMService_CSR_Supplier_Signature_ReadBlock: operation=NvMService_CSR_Supplier_Signature.ReadBlock
        DataServices_Trust_Model_CSR_Supplier_Signature_Read_Trust_Model_CSR_Supplier_Signature_ReadDataLength
        DataServices_Trust_Model_CSR_Supplier_Signature_Read_Trust_Model_CSR_Supplier_Signature_WriteData
          sync call SC_NvMService_CSR_Supplier_Signature_GetErrorStatus: operation=NvMService_CSR_Supplier_Signature.GetErrorStatus
          sync call SC_NvMService_CSR_Supplier_Signature_WriteBlock: operation=NvMService_CSR_Supplier_Signature.WriteBlock
        RoutineServices_Routine_Erase_All_Start
          18 x sync call:
            SC_NvMService_Execution_Counters_GetErrorStatus: operation=NvMService_Execution_Counters.GetErrorStatus
            SC_NvMService_Execution_Counters_SetRamBlockStatus: operation=NvMService_Execution_Counters.SetRamBlockStatus
            SC_NvMService_Measurement_Frame_12_Config_GetErrorStatus: operation=NvMService_Measurement_Frame_12_Config.GetErrorStatus
            SC_NvMService_Measurement_Frame_12_Config_SetRamBlockStatus: operation=NvMService_Measurement_Frame_12_Config.SetRamBlockStatus
            SC_NvMService_Pre_Safe_Recorder_1_GetErrorStatus: operation=NvMService_Pre_Safe_Recorder_1.GetErrorStatus
            SC_NvMService_Pre_Safe_Recorder_1_SetRamBlockStatus: operation=NvMService_Pre_Safe_Recorder_1.SetRamBlockStatus
            SC_NvMService_Pre_Safe_Recorder_2_GetErrorStatus: operation=NvMService_Pre_Safe_Recorder_2.GetErrorStatus
            SC_NvMService_Pre_Safe_Recorder_2_SetRamBlockStatus: operation=NvMService_Pre_Safe_Recorder_2.SetRamBlockStatus
            SC_NvMService_System_Context_0_GetErrorStatus: operation=NvMService_System_Context_0.GetErrorStatus
            SC_NvMService_System_Context_0_SetRamBlockStatus: operation=NvMService_System_Context_0.SetRamBlockStatus
            SC_NvMService_System_Context_1_GetErrorStatus: operation=NvMService_System_Context_1.GetErrorStatus
            SC_NvMService_System_Context_1_SetRamBlockStatus: operation=NvMService_System_Context_1.SetRamBlockStatus
            SC_NvMService_System_Context_2_GetErrorStatus: operation=NvMService_System_Context_2.GetErrorStatus
            SC_NvMService_System_Context_2_SetRamBlockStatus: operation=NvMService_System_Context_2.SetRamBlockStatus
            SC_NvMService_Tests_Param_GetErrorStatus: operation=NvMService_Tests_Param.GetErrorStatus
            SC_NvMService_Tests_Param_SetRamBlockStatus: operation=NvMService_Tests_Param.SetRamBlockStatus
            SC_NvMService_Warm_Reset_GetErrorStatus: operation=NvMService_Warm_Reset.GetErrorStatus
            SC_NvMService_Warm_Reset_SetRamBlockStatus: operation=NvMService_Warm_Reset.SetRamBlockStatus
        RoutineServices_Routine_Force_External_WDG_Start
          sync call SC_pclExtWdgTest_GetWdgTestResult: operation=pclExtWdgTest.GetWdgTestResult
          sync call SC_pclExtWdgTest_LaunchWdgTest: operation=pclExtWdgTest.LaunchWdgTest
        Snapshot_DataServices_Data_DID_0xfd05_Root_Causes
          data-receive-point-by-arguments:
            access REC_prrSnapshotData_u8SnapshotAecId: accessed-variable=prrSnapshotData.u8SnapshotAecId
        DiagFunction_MainFunction: mode-access-point=CommunicationModeMSI.Mode
          data-send-points:
            access SEND_P_ROE_ROE_XX_ST3: accessed-variable=P_ROE.ROE_XX_ST3
  swc implementation DiagFunction_Implementation: behavior=DiagFunction_InternalBehavior
